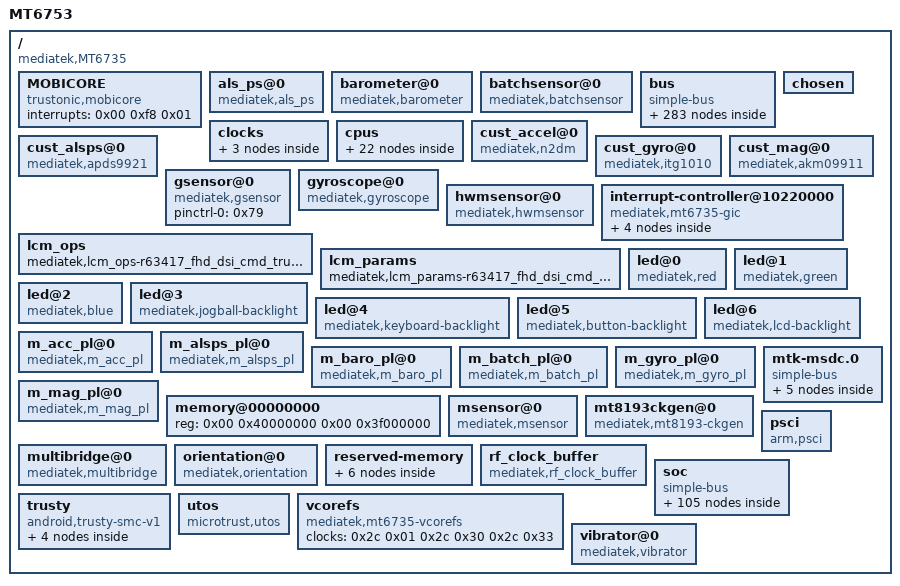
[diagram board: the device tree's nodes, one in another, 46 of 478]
/dts-v1/;

/ {
	#address-cells = <0x02>;
	#size-cells = <0x02>;
	compatible = "mediatek,MT6735";
	interrupt-parent = <0x01>;
	model = "MT6753";

	MOBICORE {
		compatible = "trustonic,mobicore";
		interrupts = <0x00 0xf8 0x01>;
	};

	als_ps@0 {
		compatible = "mediatek,als_ps";
		pinctrl-0 = <0x7a>;
		pinctrl-1 = <0x7b>;
		pinctrl-names = "pin_default\0pin_cfg";
		status = "okay";
	};

	barometer@0 {
		compatible = "mediatek,barometer";
	};

	batchsensor@0 {
		compatible = "mediatek,batchsensor";
	};

	bus {
		#address-cells = <0x01>;
		#size-cells = <0x01>;
		compatible = "simple-bus";
		ranges = <0x00 0x00 0x00 0xffffffff>;

		APMIXED@0x10209000 {
			compatible = "mediatek,APMIXED";
			reg = <0x10209000 0x1000>;
		};

		CKSYS@0x10210000 {
			compatible = "mediatek,CKSYS";
			reg = <0x10210000 0x1000>;
		};

		DEVAPC@10207000 {
			compatible = "mediatek,DEVAPC";
			interrupts = <0x00 0x86 0x08>;
			reg = <0x10207000 0x1000>;
		};

		DEVAPC_AO@10007000 {
			compatible = "mediatek,DEVAPC_AO";
			reg = <0x10007000 0x1000>;
		};

		EFUSEC@10206000 {
			compatible = "mediatek,EFUSEC";
			reg = <0x10206000 0x1000>;
		};

		EMI@0x10203000 {
			compatible = "mediatek,EMI";
			interrupts = <0x00 0x88 0x04>;
			reg = <0x10203000 0x1000>;
		};

		FHCTL@0x10209F00 {
			compatible = "mediatek,FHCTL";
			reg = <0x10209f00 0x100>;
		};

		G3D_CONFIG@0x13000000 {
			compatible = "mediatek,G3D_CONFIG";
			reg = <0x13000000 0x1000>;
		};

		INFRACFG_AO@0x10000000 {
			compatible = "mediatek,INFRACFG_AO";
			reg = <0x10000000 0x1000>;
		};

		MALI@0x13040000 {
			clock-frequency = <0x1ad27480>;
			clock-names = "mfg-main\0mfg-smi-common\0mtcmos-mfg\0mtcmos-display";
			clocks = <0x78 0x01 0x29 0x01 0x2d 0x05 0x2d 0x04>;
			compatible = "arm,malit720\0arm,mali-t72x\0arm,malit7xx\0arm,mali-midgard";
			interrupt-names = "JOB\0MMU\0GPU";
			interrupts = <0x00 0xd6 0x08 0x00 0xd5 0x08 0x00 0xd4 0x08>;
			reg = <0x13040000 0x4000>;
		};

		MCUCFG@0x10200000 {
			compatible = "mediatek,MCUCFG";
			interrupts = <0x00 0x47 0x04>;
			reg = <0x10200000 0x200>;
		};

		MTKFB@5e200000 {
			compatible = "mediatek,MTKFB";
			reg = <0x7f000000 0x1000000>;
		};

		PERICFG@0x10002000 {
			compatible = "mediatek,PERICFG";
			reg = <0x10002000 0x1000>;
		};

		SLEEP@0x10006000 {
			compatible = "mediatek,SLEEP";
			interrupts = <0x00 0xa5 0x08 0x00 0xa6 0x08 0x00 0xa7 0x08 0x00 0xa8 0x08>;
			reg = <0x10006000 0x1000>;
		};

		accdet@ {
			accdet-mic-mode = <0x01>;
			accdet-mic-vol = <0x07>;
			accdet-plugout-debounce = <0x14>;
			compatible = "mediatek,mt6735-accdet\0mediatek,mt6735m-accdet\0mediatek,mt6753-accdet";
			debounce = <0x05 0x3e800>;
			headset-four-key-threshold = <0x00 0x3a 0x79 0xc0 0x1c2>;
			headset-mode-setting = <0x146 0x82 0x01 0x44 0x800 0x800 0x20>;
			headset-three-key-threshold = <0x00 0x50 0xdc 0x1f4>;
			interrupt-parent = <0x0b>;
			interrupts = <0x05 0x08>;
			pinctrl-0 = <0x6d>;
			pinctrl-1 = <0x6e>;
			pinctrl-names = "default\0state_eint_as_int";
			status = "okay";
		};

		audio@11220000 {
			compatible = "mediatek,audio";
			interrupts = <0x00 0x90 0x08>;
			reg = <0x11220000 0x10000>;
		};

		bat_comm {
			compatible = "mediatek,battery";
		};

		bat_meter {
			compatible = "mediatek,bat_meter";
		};

		bat_notify {
			compatible = "mediatek,bat_notify";
		};

		btcvsd@10000000 {
			compatible = "mediatek,audio_bt_cvsd";
			interrupts = <0x00 0xe6 0x08>;
			offset = <0x700 0x800 0xfd0 0xfd4 0xfd8>;
			reg = <0x10000000 0x1000 0x18000000 0x10000 0x18080000 0x8000>;
		};

		bus_dbg@10208000 {
			compatible = "mediatek,bus_dbg-v1";
			interrupts = <0x00 0x89 0x08>;
			reg = <0x10208000 0x1000>;
		};

		c2k_sdio@0 {
			compatible = "mediatek,mt6735-c2k_sdio";
			interrupts = <0x00 0xde 0x08>;
		};

		ccci_off@0 {
			clock-names = "scp-sys-md1-main";
			clocks = <0x2d 0x01>;
			compatible = "mediatek,ccci_off";
		};

		cpu_dbgapb@10810000 {
			compatible = "mediatek,mt6735-dbg_debug";
			num = <0x08>;
			reg = <0x10810000 0x1000 0x10910000 0x1000 0x10a10000 0x1000 0x10b10000 0x1000 0x10c10000 0x1000 0x10d10000 0x1000 0x10e10000 0x1000 0x10f10000 0x1000>;
		};

		cqdma@10217c00 {
			compatible = "mediatek,cqdma";
			interrupts = <0x00 0x8f 0x08>;
			nr_channel = <0x01>;
			reg = <0x10217c00 0xc00>;
		};

		dbgapb_base@1011A000 {
			compatible = "mediatek,dbgapb_base";
			reg = <0x1011a000 0x100>;
		};

		dispsys@14007000 {
			compatible = "mediatek,dispsys";
			interrupts = <0x00 0xc1 0x08 0x00 0xd3 0x08 0x00 0xc2 0x08 0x00 0xc3 0x08 0x00 0xc4 0x08 0x00 0xc5 0x08 0x00 0xc6 0x08 0x00 0xc7 0x08 0x00 0xc8 0x08 0x00 0xc9 0x08 0x00 0x00 0x08 0x00 0x75 0x08 0x00 0x00 0x08 0x00 0xba 0x08 0x00 0xcb 0x08 0x00 0xcc 0x08 0x00 0xcd 0x08 0x00 0xb0 0x08 0x00 0x00 0x08 0x00 0x00 0x08 0x00 0x00 0x08 0x00 0x00 0x08 0x00 0x00 0x08 0x00 0x00 0x08 0x00 0x00 0x08 0x00 0x00 0x08 0x00 0x00 0x08 0x00 0x00 0x08 0x00 0x00 0x08 0x00 0x00 0x08 0x00 0x00 0x08 0x00 0xd2 0x08 0x00 0x00 0x08>;
			reg = <0x14007000 0x1000 0x14008000 0x1000 0x14009000 0x1000 0x1400a000 0x1000 0x1400b000 0x1000 0x1400c000 0x1000 0x1400d000 0x1000 0x1400e000 0x1000 0x1400f000 0x1000 0x14010000 0x1000 0x00 0x00 0x1100e000 0x1000 0x00 0x00 0x14015000 0x1000 0x14013000 0x1000 0x14014000 0x1000 0x14000000 0x1000 0x14016000 0x1000 0x14017000 0x1000 0x14018000 0x1000 0x10206000 0x1000 0x10210000 0x1000 0x10211a70 0x0c 0x10211974 0x0c 0x10211b70 0x0c 0x10206044 0x0c 0x10206514 0x0c 0x10206558 0x0c 0x102100a0 0x1000 0x10209260 0x1000 0x10209264 0x1000 0x14012000 0x1000 0x10209000 0x1000>;
		};

		dma@11000000 {
			compatible = "mediatek,ap_dma";
			interrupts = <0x00 0x72 0x08>;
			reg = <0x11000000 0x1000>;
		};

		eintc@10005000 {
			#interrupt-cells = <0x02>;
			compatible = "mediatek,mt-eic";
			interrupt-controller;
			interrupts = <0x00 0x99 0x04>;
			linux,phandle = <0x0b>;
			mediatek,deint_possible_irq = <0xbb 0xbc 0xbd 0xbe>;
			mediatek,mapping_table_entry = <0x00>;
			mediatek,max_deint_cnt = <0x04>;
			mediatek,max_eint_num = <0xd5>;
			phandle = <0x0b>;
			reg = <0x10005000 0x1000>;

			MD1_SIM1_HOT_PLUG_EINT@0 {
				compatible = "mediatek,MD1_SIM1_HOT_PLUG_EINT-eint";
				debounce = <0x00 0x186a0>;
				dedicated = <0x00 0x00>;
				interrupts = <0x00 0x08>;
				sockettype = <0x00 0x00>;
				src_pin = <0x00 0x00>;
				status = "okay";
			};

			pmic@206 {
				compatible = "mediatek, pmic-eint";
				debounce = <0xce 0x3e8>;
				interrupt-parent = <0x0b>;
				interrupts = <0xce 0x04>;
			};
		};

		gcpu@10216000 {
			compatible = "mediatek,gcpu";
			interrupts = <0x00 0x96 0x08>;
			reg = <0x10216000 0x1000>;
		};

		gf518m {
			compatible = "mediatek,gf518m";
			debounce = <0x08 0x00>;
			gf518m_vendor_gpio = <0x09 0x4e 0x00>;
			interrupt-parent = <0x0b>;
			interrupts = <0x08 0x08>;
			pinctrl-0 = <0x6f>;
			pinctrl-1 = <0x70>;
			pinctrl-2 = <0x71>;
			pinctrl-3 = <0x72>;
			pinctrl-4 = <0x73>;
			pinctrl-5 = <0x74>;
			pinctrl-6 = <0x75>;
			pinctrl-7 = <0x76>;
			pinctrl-8 = <0x77>;
			pinctrl-names = "pin_default\0goodix_pin_irq\0gf518m_reset_high\0gf518m_reset_low\0gf518m_miso_spi\0gf518m_mosi_spi\0gf518m_vendor_pu\0gf518m_vendor_pd\0goodix_pin_irq_pd";
			status = "okay";
			vgf518m-supply = <0x66>;
		};

		gps {
			compatible = "mediatek,mt3326-gps";
		};

		hallkey {
			compatible = "mediatek,mt6735-hallkey";
			debounce = <0x04 0x00>;
			interrupt-parent = <0x0b>;
			interrupts = <0x04 0x02>;
			status = "okay";
		};

		i2c@11007000 {
			#address-cells = <0x01>;
			#size-cells = <0x00>;
			cell-index = <0x00>;
			compatible = "mediatek,mt6753-i2c";
			def_speed = <0x64>;
			interrupts = <0x00 0x54 0x08 0x00 0x62 0x08>;
			reg = <0x11007000 0x1000>;

			cam_cal_drv@31 {
				compatible = "mediatek,cam_cal_drv";
				reg = <0x31>;
				status = "okay";
			};

			camera_main@10 {
				compatible = "mediatek,camera_main";
				reg = <0x10>;
				status = "okay";
			};

			camera_main_af@0c {
				compatible = "mediatek,camera_main_af";
				reg = <0x0c>;
				status = "okay";
			};

			camera_sub@3c {
				compatible = "mediatek,camera_sub";
				reg = <0x3c>;
				status = "okay";
			};
		};

		i2c@11008000 {
			#address-cells = <0x01>;
			#size-cells = <0x00>;
			cell-index = <0x01>;
			compatible = "mediatek,mt6753-i2c";
			def_speed = <0x64>;
			interrupts = <0x00 0x55 0x08 0x00 0x63 0x08>;
			reg = <0x11008000 0x1000>;

			cap_touch@38 {
				compatible = "mediatek,cap_touch";
				reg = <0x38>;
				status = "okay";
			};

			i2c_lcd_bias@73 {
				compatible = "mediatek,i2c_lcd_bias";
				reg = <0x73>;
				status = "okay";
			};

			strobe_main@30 {
				compatible = "mediatek,strobe_main";
				reg = <0x30>;
				status = "okay";
			};

			strobe_sub@32 {
				compatible = "mediatek,strobe_sub";
				reg = <0x32>;
				status = "okay";
			};

			synaptics_touch@20 {
				compatible = "mediatek,synaptics_touch";
				reg = <0x20>;
				status = "okay";
			};
		};

		i2c@11009000 {
			#address-cells = <0x01>;
			#size-cells = <0x00>;
			cell-index = <0x02>;
			compatible = "mediatek,mt6753-i2c";
			def_speed = <0x64>;
			interrupts = <0x00 0x56 0x08 0x00 0x64 0x08>;
			reg = <0x11009000 0x1000>;

			alsps@53 {
				compatible = "mediatek,alsps";
				reg = <0x53>;
				status = "okay";
			};

			flash@45 {
				compatible = "mediatek,flash";
				reg = <0x45>;
				status = "okay";
			};

			gsensor@09 {
				compatible = "mediatek,gsensor";
				reg = <0x09>;
				status = "okay";
			};

			gyro@68 {
				compatible = "mediatek,gyro";
				reg = <0x68>;
				status = "okay";
			};

			msensor@0c {
				compatible = "mediatek,msensor";
				reg = <0x0c>;
				status = "okay";
			};

			nfc@28 {
				compatible = "mediatek,nfc";
				reg = <0x28>;
				status = "okay";
			};
		};

		i2c@1100f000 {
			#address-cells = <0x01>;
			#size-cells = <0x00>;
			cell-index = <0x03>;
			compatible = "mediatek,mt6753-i2c";
			def_speed = <0x64>;
			interrupts = <0x00 0x57 0x08 0x00 0x65 0x08>;
			reg = <0x1100f000 0x1000>;
		};

		i2c@11012000 {
			#address-cells = <0x01>;
			#size-cells = <0x00>;
			cell-index = <0x04>;
			compatible = "mediatek,mt6753-i2c";
			def_speed = <0x64>;
			interrupts = <0x00 0x58 0x08 0x00 0x66 0x08>;
			reg = <0x11012000 0x1000>;
		};

		lcm {
			compatible = "mediatek,mt6753p1_64-lcm";
		};

		lcm_mode {
			compatible = "mediatek,lcm_mode";
			lcm_bl_gpio = <0x09 0x81 0x00>;
			lcm_power_gpio = <0x09 0x50 0x00>;
			pinctrl-0 = <0x50>;
			pinctrl-1 = <0x51>;
			pinctrl-2 = <0x52>;
			pinctrl-3 = <0x53>;
			pinctrl-4 = <0x54>;
			pinctrl-5 = <0x55>;
			pinctrl-6 = <0x56>;
			pinctrl-7 = <0x57>;
			pinctrl-8 = <0x58>;
			pinctrl-names = "default\0lcm_mode_00\0lcm_mode_01\0lcm_mode_02\0lcm_mode_03\0lcm_mode_04\0lcm_mode_05\0lcm_mode_06\0lcm_mode_07";
			status = "okay";
		};

		m4u@10205000 {
			cell-index = <0x00>;
			clock-names = "infra_m4u\0smi_common\0m4u_disp0_smi_larb0\0m4u_vdec0_vdec\0m4u_vdec1_larb\0m4u_img_image_larb2_smi\0m4u_venc_venc\0m4u_venc_larb";
			clocks = <0x16 0x09 0x29 0x01 0x29 0x02 0x2a 0x01 0x2a 0x02 0x32 0x01 0x2b 0x02 0x2b 0x01>;
			compatible = "mediatek,m4u";
			interrupts = <0x00 0x92 0x08>;
			reg = <0x10205000 0x1000>;
		};

		mcucfg@10200000 {
			compatible = "mediatek,mt6735-mcucfg";
			interrupts = <0x00 0x47 0x04>;
			reg = <0x10200000 0x200>;
		};

		mdc2k@3a00b01c {
			clock-names = "scp-sys-md2-main";
			clocks = <0x2d 0x02>;
			compatible = "mediatek,mdc2k";
			interrupts = <0x00 0xdd 0x02>;
			reg = <0x3a00b01c 0x10 0x1021c800 0x300 0x1021d800 0x300>;
		};

		mdcldma@1000A000 {
			compatible = "mediatek,mdcldma";
			interrupts = <0x00 0x91 0x04 0x00 0x8c 0x08 0x00 0xdf 0x02>;
			mediatek,cldma_capability = <0x02>;
			mediatek,md_id = <0x00>;
			mediatek,md_smem_size = <0x10000>;
			pinctrl-0 = <0x46>;
			pinctrl-1 = <0x47>;
			pinctrl-2 = <0x48>;
			pinctrl-3 = <0x49>;
			pinctrl-4 = <0x4a>;
			pinctrl-names = "default\0vsram_output_low\0vsram_output_high\0RFIC0_01_mode\0RFIC0_04_mode";
			reg = <0x1000a000 0x1000 0x1000b000 0x1000 0x1021a000 0x1000 0x1021b000 0x1000 0x1020a000 0x1000 0x1020b000 0x1000>;
		};

		mhl@0 {
			compatible = "mediatek,sii8348-hdmi";
		};

		mt_soc_codec_dummy_name@11220000 {
			compatible = "mediatek,mt_soc_codec_dummy";
		};

		mt_soc_codec_name@11220000 {
			compatible = "mediatek,mt_soc_codec_63xx";
		};

		mt_soc_dai_name@11220000 {
			compatible = "mediatek,mt_soc_dai_stub";
		};

		mt_soc_dl1_awb_pcm@11220000 {
			compatible = "mediatek,mt_soc_pcm_dl1_awb";
		};

		mt_soc_dl1_pcm@11220000 {
			audclk-gpio = <0x8f 0x00>;
			audmiso-gpio = <0x90 0x00>;
			audmosi-gpio = <0x91 0x00>;
			compatible = "mediatek,mt-soc-dl1-pcm";
			extspkamp-gpio = <0x75 0x00>;
			i2s1clk-gpio = <0x50 0x00>;
			i2s1dat-gpio = <0x4e 0x00>;
			i2s1mclk-gpio = <0x09 0x00>;
			i2s1ws-gpio = <0x4f 0x00>;
			interrupts = <0x00 0x90 0x08>;
			reg = <0x11220000 0x1000>;
			vowclk-gpio = <0x94 0x00>;
		};

		mt_soc_dl2_pcm@11220000 {
			compatible = "mediatek,mt_soc_pcm_dl2";
		};

		mt_soc_dummy_pcm@11220000 {
			compatible = "mediatek,mt_soc_pcm_dummy";
		};

		mt_soc_fm_i2s_awb_pcm@11220000 {
			compatible = "mediatek,mt_soc_pcm_fm_i2s_awb";
		};

		mt_soc_fm_i2s_pcm@11220000 {
			compatible = "mediatek,mt_soc_pcm_fm_i2s";
		};

		mt_soc_fm_mrgtx_pcm@11220000 {
			compatible = "mediatek,mt_soc_pcm_fmtx";
		};

		mt_soc_hdmi_pcm@11220000 {
			compatible = "mediatek,mt_soc_pcm_hdmi";
		};

		mt_soc_hp_impedance_pcm@11220000 {
			compatible = "mediatek,Mt_soc_pcm_hp_impedance";
		};

		mt_soc_i2s0_awb_pcm@11220000 {
			compatible = "mediatek,mt_soc_pcm_i2s0_awb";
		};

		mt_soc_i2s0_pcm@11220000 {
			compatible = "mediatek,mt_soc_pcm_dl1_i2s0";
		};

		mt_soc_i2s0dl1_pcm@11220000 {
			compatible = "mediatek,mt_soc_pcm_dl1_i2s0Dl1";
		};

		mt_soc_mrgrx_awb_pcm@11220000 {
			compatible = "mediatek,mt_soc_pcm_mrgrx_awb";
		};

		mt_soc_mrgrx_pcm@11220000 {
			compatible = "mediatek,mt_soc_pcm_mrgrx";
		};

		mt_soc_offload_gdma@11220000 {
			compatible = "mediatek,mt_soc_pcm_offload_gdma";
		};

		mt_soc_routing_dai_name@11220000 {
			compatible = "mediatek,mt_soc_dai_routing";
		};

		mt_soc_routing_pcm@11220000 {
			compatible = "mediatek,mt_soc_pcm_routing";
			i2s1clk-gpio = <0x07 0x06>;
			i2s1dat-gpio = <0x05 0x06>;
			i2s1mclk-gpio = <0x09 0x06>;
			i2s1ws-gpio = <0x06 0x06>;
		};

		mt_soc_tdmrx_pcm@11220000 {
			compatible = "mediatek,mt_soc_tdm_capture";
		};

		mt_soc_ul1_pcm@11220000 {
			compatible = "mediatek,mt_soc_pcm_capture";
		};

		mt_soc_ul2_pcm@11220000 {
			compatible = "mediatek,mt_soc_pcm_capture2";
		};

		mt_soc_uldlloopback_pcm@11220000 {
			compatible = "mediatek,mt_soc_pcm_uldlloopback";
		};

		mt_soc_voice_md1@11220000 {
			compatible = "mediatek,mt_soc_pcm_voice_md1";
		};

		mt_soc_voice_md1_bt@11220000 {
			compatible = "mediatek,mt_soc_pcm_voice_md1_bt";
		};

		mt_soc_voice_md2@11220000 {
			compatible = "mediatek,mt_soc_pcm_voice_md2";
		};

		mt_soc_voice_md2_bt@11220000 {
			compatible = "mediatek,mt_soc_pcm_voice_md2_bt";
		};

		mt_soc_voip_bt_in@11220000 {
			compatible = "mediatek,mt_soc_pcm_bt_dai";
		};

		mt_soc_voip_bt_out@11220000 {
			compatible = "mediatek,mt_soc_pcm_dl1_bt";
		};

		nfc@0 {
			compatible = "mediatek,nfc-gpio-v2";
			gpio-eint = <0x01>;
			gpio-irq = <0x02>;
			gpio-rst = <0x03>;
			gpio-ven = <0x04>;
			pinctrl-0 = <0x2e>;
			pinctrl-1 = <0x5a>;
			pinctrl-2 = <0x5b>;
			pinctrl-3 = <0x5c>;
			pinctrl-4 = <0x5d>;
			pinctrl-5 = <0x5e>;
			pinctrl-6 = <0x5f>;
			pinctrl-7 = <0x60>;
			pinctrl-names = "default\0ven_high\0ven_low\0rst_high\0rst_low\0eint_high\0eint_low\0irq_init";
			status = "okay";
		};

		pinctrl {
			#gpio-cells = <0x02>;
			compatible = "mediatek,mt6735-pinctrl";
			gpio-controller;
			linux,phandle = <0x09>;
			mediatek,pctl-regmap = <0x59>;
			phandle = <0x09>;
			pins-are-numbered;
			reg = <0x00 0x9bceb8 0x00 0x3e8>;

			8193ckgen_default {
				linux,phandle = <0x7e>;
				phandle = <0x7e>;
			};

			8193ckgen_dpi {
				linux,phandle = <0x80>;
				phandle = <0x80>;

				pins_cmd_dat {
					pins = <0x02>;
				};
			};

			8193ckgen_gpio {
				linux,phandle = <0x7f>;
				phandle = <0x7f>;

				pins_cmd_dat {
					bias-pull-up = <0x00>;
					output-high;
					pins = <0x00>;
					slew-rate = <0x01>;
				};
			};

			alspsdefaultcfg {
				linux,phandle = <0x7a>;
				phandle = <0x7a>;
			};

			alspspincfg {
				linux,phandle = <0x7b>;
				phandle = <0x7b>;

				pins_cmd_dat {
					bias-pull-up = <0x00>;
					pins = <0x200>;
					slew-rate = <0x00>;
				};
			};

			cam0@0 {
				linux,phandle = <0x38>;
				phandle = <0x38>;

				pins_cmd_dat {
					output-low;
					pins = <0x2c00>;
					slew-rate = <0x01>;
				};
			};

			cam0@1 {
				linux,phandle = <0x39>;
				phandle = <0x39>;

				pins_cmd_dat {
					output-high;
					pins = <0x2c00>;
					slew-rate = <0x01>;
				};
			};

			cam0@2 {
				linux,phandle = <0x3a>;
				phandle = <0x3a>;

				pins_cmd_dat {
					output-low;
					pins = <0x700>;
					slew-rate = <0x01>;
				};
			};

			cam0@3 {
				linux,phandle = <0x3b>;
				phandle = <0x3b>;

				pins_cmd_dat {
					output-high;
					pins = <0x700>;
					slew-rate = <0x01>;
				};
			};

			cam1@0 {
				linux,phandle = <0x3c>;
				phandle = <0x3c>;

				pins_cmd_dat {
					output-low;
					pins = <0xb00>;
					slew-rate = <0x01>;
				};
			};

			cam1@1 {
				linux,phandle = <0x3d>;
				phandle = <0x3d>;

				pins_cmd_dat {
					output-high;
					pins = <0xb00>;
					slew-rate = <0x01>;
				};
			};

			cam1@2 {
				linux,phandle = <0x3e>;
				phandle = <0x3e>;

				pins_cmd_dat {
					output-low;
					pins = <0xc00>;
					slew-rate = <0x01>;
				};
			};

			cam1@3 {
				linux,phandle = <0x3f>;
				phandle = <0x3f>;

				pins_cmd_dat {
					output-high;
					pins = <0xc00>;
					slew-rate = <0x01>;
				};
			};

			cam@0 {
				linux,phandle = <0x40>;
				phandle = <0x40>;

				pins_cmd_dat {
					output-low;
					pins = <0x3f00>;
					slew-rate = <0x01>;
				};
			};

			cam@1 {
				linux,phandle = <0x41>;
				phandle = <0x41>;

				pins_cmd_dat {
					output-high;
					pins = <0x3f00>;
					slew-rate = <0x01>;
				};
			};

			cam@2 {
				linux,phandle = <0x42>;
				phandle = <0x42>;

				pins_cmd_dat {
					output-low;
					pins = <0x4000>;
					slew-rate = <0x01>;
				};
			};

			cam@3 {
				linux,phandle = <0x43>;
				phandle = <0x43>;

				pins_cmd_dat {
					output-high;
					pins = <0x4000>;
					slew-rate = <0x01>;
				};
			};

			camdefault {
				linux,phandle = <0x37>;
				phandle = <0x37>;
			};

			clockbuf@1 {
				linux,phandle = <0x49>;
				phandle = <0x49>;

				pins_cmd0_dat {
					pins = <0x6e01>;
				};

				pins_cmd1_dat {
					pins = <0x6f01>;
				};

				pins_cmd2_dat {
					pins = <0x7001>;
				};

				pins_cmd3_dat {
					pins = <0x7101>;
				};

				pins_cmd4_dat {
					pins = <0x7201>;
				};
			};

			clockbuf@2 {
				linux,phandle = <0x4a>;
				phandle = <0x4a>;

				pins_cmd0_dat {
					pins = <0x6e04>;
				};

				pins_cmd1_dat {
					pins = <0x6f04>;
				};

				pins_cmd2_dat {
					pins = <0x7004>;
				};

				pins_cmd3_dat {
					pins = <0x7104>;
				};

				pins_cmd4_dat {
					pins = <0x7204>;
				};
			};

			default {
				linux,phandle = <0x2e>;
				phandle = <0x2e>;
			};

			drvvbus_high {
				linux,phandle = <0x65>;
				phandle = <0x65>;

				pins_cmd_dat {
					bias-pull-down = <0x00>;
					output-high;
					pins = <0x5300>;
					slew-rate = <0x01>;
				};
			};

			drvvbus_init {
				linux,phandle = <0x63>;
				phandle = <0x63>;

				pins_cmd_dat {
					bias-pull-up = <0x00>;
					pins = <0x5300>;
					slew-rate = <0x01>;
				};
			};

			drvvbus_low {
				linux,phandle = <0x64>;
				phandle = <0x64>;

				pins_cmd_dat {
					bias-pull-down = <0x00>;
					output-low;
					pins = <0x5300>;
					slew-rate = <0x01>;
				};
			};

			eint0default {
				linux,phandle = <0x67>;
				phandle = <0x67>;
			};

			eint5default {
				linux,phandle = <0x6d>;
				phandle = <0x6d>;
			};

			eint@0 {
				linux,phandle = <0x68>;
				phandle = <0x68>;

				pins_cmd_dat {
					bias-disable;
					pins = <0x900>;
					slew-rate = <0x00>;
				};
			};

			eint@5 {
				linux,phandle = <0x6e>;
				phandle = <0x6e>;

				pins_cmd_dat {
					bias-disable;
					pins = <0x500>;
					slew-rate = <0x00>;
				};
			};

			eintoutput0 {
				linux,phandle = <0x69>;
				phandle = <0x69>;

				pins_cmd_dat {
					output-low;
					pins = <0x900>;
					slew-rate = <0x01>;
				};
			};

			eintoutput1 {
				linux,phandle = <0x6a>;
				phandle = <0x6a>;

				pins_cmd_dat {
					output-high;
					pins = <0x900>;
					slew-rate = <0x01>;
				};
			};

			flashlight@0 {
				linux,phandle = <0x44>;
				phandle = <0x44>;

				pins_cmd_dat {
					output-low;
					pins = <0x4d00>;
					slew-rate = <0x01>;
				};
			};

			flashlight@1 {
				linux,phandle = <0x45>;
				phandle = <0x45>;

				pins_cmd_dat {
					output-high;
					pins = <0x4d00>;
					slew-rate = <0x01>;
				};
			};

			gf518m_miso_spi {
				linux,phandle = <0x73>;
				phandle = <0x73>;

				pins_cmd_dat {
					bias-pull-up = <0x00>;
					pins = <0x4301>;
					slew-rate = <0x00>;
				};
			};

			gf518m_mosi_spi {
				linux,phandle = <0x74>;
				phandle = <0x74>;

				pins_cmd_dat {
					bias-pull-up = <0x00>;
					output-high;
					pins = <0x4401>;
					slew-rate = <0x01>;
				};
			};

			gf518m_reset_high {
				linux,phandle = <0x71>;
				phandle = <0x71>;

				pins_cmd_dat {
					bias-disable;
					output-high;
					pins = <0xa00>;
					slew-rate = <0x01>;
				};
			};

			gf518m_reset_low {
				linux,phandle = <0x72>;
				phandle = <0x72>;

				pins_cmd_dat {
					bias-disable;
					output-low;
					pins = <0xa00>;
					slew-rate = <0x01>;
				};
			};

			gf518m_vendor_pd {
				linux,phandle = <0x76>;
				phandle = <0x76>;

				pins_cmd_dat {
					bias-pull-down = <0x00>;
					pins = <0x4e00>;
					slew-rate = <0x00>;
				};
			};

			gf518m_vendor_pu {
				linux,phandle = <0x75>;
				phandle = <0x75>;

				pins_cmd_dat {
					bias-pull-up = <0x00>;
					output-high;
					pins = <0x4e00>;
					slew-rate = <0x00>;
				};
			};

			goodix_pin_irq {
				linux,phandle = <0x70>;
				phandle = <0x70>;

				pins_cmd_dat {
					bias-disable;
					pins = <0x800>;
					slew-rate = <0x00>;
				};
			};

			goodix_pin_irq_pd {
				linux,phandle = <0x77>;
				phandle = <0x77>;

				pins_cmd_dat {
					bias-pull-down = <0x00>;
					pins = <0x800>;
					slew-rate = <0x00>;
				};
			};

			gpslna@0 {
				linux,phandle = <0x2f>;
				phandle = <0x2f>;

				pins_cmd_dat {
					bias-disable;
					output-low;
					pins = <0x4f00>;
					slew-rate = <0x00>;
				};
			};

			gpslna@1 {
				linux,phandle = <0x30>;
				phandle = <0x30>;

				pins_cmd_dat {
					output-high;
					pins = <0x4f00>;
					slew-rate = <0x01>;
				};
			};

			gpslna@2 {
				linux,phandle = <0x31>;
				phandle = <0x31>;

				pins_cmd_dat {
					output-low;
					pins = <0x4f00>;
					slew-rate = <0x01>;
				};
			};

			gsensorpincfg {
				linux,phandle = <0x79>;
				phandle = <0x79>;

				pins_cmd_dat {
					bias-pull-down = <0x00>;
					pins = <0x700>;
					slew-rate = <0x00>;
				};
			};

			gyrodefaultcfg {
				linux,phandle = <0x7c>;
				phandle = <0x7c>;
			};

			gyropincfg {
				linux,phandle = <0x7d>;
				phandle = <0x7d>;

				pins_cmd_dat {
					bias-pull-down = <0x00>;
					pins = <0x4300>;
					slew-rate = <0x00>;
				};
			};

			iddig_irq_init {
				linux,phandle = <0x62>;
				phandle = <0x62>;

				pins_cmd_dat {
					bias-pull-up = <0x00>;
					pins = <0x01>;
					slew-rate = <0x00>;
				};
			};

			lcm_mode@0 {
				linux,phandle = <0x51>;
				phandle = <0x51>;

				pins_cmd_dat {
					pins = <0x5000>;
				};
			};

			lcm_mode@1 {
				linux,phandle = <0x52>;
				phandle = <0x52>;

				pins_cmd_dat {
					pins = <0x5001>;
				};
			};

			lcm_mode@2 {
				linux,phandle = <0x53>;
				phandle = <0x53>;

				pins_cmd_dat {
					pins = <0x5002>;
				};
			};

			lcm_mode@3 {
				linux,phandle = <0x54>;
				phandle = <0x54>;

				pins_cmd_dat {
					pins = <0x5003>;
				};
			};

			lcm_mode@4 {
				linux,phandle = <0x55>;
				phandle = <0x55>;

				pins_cmd_dat {
					pins = <0x5004>;
				};
			};

			lcm_mode@5 {
				linux,phandle = <0x56>;
				phandle = <0x56>;

				pins_cmd_dat {
					pins = <0x5005>;
				};
			};

			lcm_mode@6 {
				linux,phandle = <0x57>;
				phandle = <0x57>;

				pins_cmd_dat {
					pins = <0x5006>;
				};
			};

			lcm_mode@7 {
				linux,phandle = <0x58>;
				phandle = <0x58>;

				pins_cmd_dat {
					pins = <0x5007>;
				};
			};

			lcm_mode_default {
				linux,phandle = <0x50>;
				phandle = <0x50>;

				pins_cmd_dat {
					pins = <0x5000>;
				};
			};

			mmc0@default {
				linux,phandle = <0x02>;
				phandle = <0x02>;

				pins_clk {
					drive-strength = [02];
				};

				pins_cmd {
					drive-strength = [02];
				};

				pins_dat {
					drive-strength = [02];
				};

				pins_ds {
					drive-strength = [02];
				};

				pins_rst {
					drive-strength = [02];
				};
			};

			mmc0@register_default {
				cmd_edge = [01];
				cmdrddly = [00];
				cmdrrddly = [00];
				dat0rddly = [00];
				dat1rddly = [00];
				dat2rddly = [00];
				dat3rddly = [00];
				dat4rddly = [00];
				dat5rddly = [00];
				dat6rddly = [00];
				dat7rddly = [00];
				datwrddly = [00];
				ett-hs200-cells = <0x0c>;
				ett-hs200-default = <0xb0 0x380 0x00 0xb0 0x7c00 0x00 0xb4 0x38 0x01 0x04 0x02 0x01 0xf0 0x1f0000 0x0f 0xf0 0x7c00000 0x00 0xb4 0x07 0x01 0xf0 0x1f 0x0f 0x04 0x400 0x01 0xf8 0x1f000000 0x0f 0xf0 0x1f00 0x16 0x04 0x04 0x00>;
				ett-hs400-cells = <0x08>;
				ett-hs400-default = <0xb0 0x380 0x00 0xb0 0x7c00 0x00 0x188 0x7c 0x02 0x188 0x1f000 0x0e 0xb4 0x38 0x01 0x04 0x02 0x00 0xf0 0x1f0000 0x0f 0xf0 0x7c00000 0x0d>;
				linux,phandle = <0x03>;
				phandle = <0x03>;
				rdata_edge = [01];
				wdata_edge = [01];
			};

			mmc1@ddr50 {
				linux,phandle = <0x07>;
				phandle = <0x07>;

				pins_clk {
					drive-strength = [03];
				};

				pins_cmd {
					drive-strength = [02];
				};

				pins_dat {
					drive-strength = [02];
				};
			};

			mmc1@default {
				linux,phandle = <0x04>;
				phandle = <0x04>;

				pins_clk {
					drive-strength = [03];
				};

				pins_cmd {
					drive-strength = [03];
				};

				pins_dat {
					drive-strength = [03];
				};
			};

			mmc1@register_default {
				cmd_edge = [01];
				cmdrddly = [00];
				cmdrrddly = [00];
				dat0rddly = [00];
				dat1rddly = [00];
				dat2rddly = [00];
				dat3rddly = [00];
				datwrddly = [00];
				linux,phandle = <0x08>;
				phandle = <0x08>;
				rdata_edge = [01];
				wdata_edge = [01];
			};

			mmc1@sdr104 {
				linux,phandle = <0x05>;
				phandle = <0x05>;

				pins_clk {
					drive-strength = [03];
				};

				pins_cmd {
					drive-strength = [02];
				};

				pins_dat {
					drive-strength = [02];
				};
			};

			mmc1@sdr50 {
				linux,phandle = <0x06>;
				phandle = <0x06>;

				pins_clk {
					drive-strength = [03];
				};

				pins_cmd {
					drive-strength = [02];
				};

				pins_dat {
					drive-strength = [02];
				};
			};

			pin_default {
				linux,phandle = <0x6f>;
				phandle = <0x6f>;
			};

			rstoutput0 {
				linux,phandle = <0x6b>;
				phandle = <0x6b>;

				pins_cmd_dat {
					output-low;
					pins = <0x3e00>;
					slew-rate = <0x01>;
				};
			};

			rstoutput1 {
				linux,phandle = <0x6c>;
				phandle = <0x6c>;

				pins_cmd_dat {
					output-high;
					pins = <0x3e00>;
					slew-rate = <0x01>;
				};
			};

			ssw0default {
				linux,phandle = <0x4b>;
				phandle = <0x4b>;
			};

			ssw@1 {
				linux,phandle = <0x4c>;
				phandle = <0x4c>;

				pins_cmd0_dat {
					pins = <0x805>;
				};

				pins_cmd1_dat {
					pins = <0x904>;
				};
			};

			ssw@2 {
				linux,phandle = <0x4d>;
				phandle = <0x4d>;

				pins_cmd0_dat {
					pins = <0x802>;
				};

				pins_cmd1_dat {
					pins = <0x904>;
				};
			};

			ssw@3 {
				linux,phandle = <0x4e>;
				phandle = <0x4e>;

				pins_cmd0_dat {
					pins = <0xa301>;
					slew-rate = <0x01>;
				};

				pins_cmd1_dat {
					pins = <0xa401>;
					slew-rate = <0x01>;
				};

				pins_cmd2_dat {
					bias-pull-up = <0x00>;
					pins = <0xa501>;
					slew-rate = <0x00>;
				};

				pins_cmd3_dat {
					pins = <0xa001>;
					slew-rate = <0x01>;
				};

				pins_cmd4_dat {
					pins = <0xa101>;
					slew-rate = <0x01>;
				};

				pins_cmd5_dat {
					bias-pull-up = <0x00>;
					pins = <0xa201>;
					slew-rate = <0x00>;
				};
			};

			ssw@4 {
				linux,phandle = <0x4f>;
				phandle = <0x4f>;

				pins_cmd0_dat {
					pins = <0xa304>;
				};

				pins_cmd1_dat {
					pins = <0xa404>;
				};

				pins_cmd2_dat {
					pins = <0xa504>;
				};

				pins_cmd3_dat {
					pins = <0xa001>;
				};

				pins_cmd4_dat {
					pins = <0xa101>;
				};

				pins_cmd5_dat {
					pins = <0xa201>;
				};
			};

			state_eint_high {
				linux,phandle = <0x5e>;
				phandle = <0x5e>;

				pins_cmd_dat {
					output-high;
					pins = <0x100>;
					slew-rate = <0x01>;
				};
			};

			state_eint_low {
				linux,phandle = <0x5f>;
				phandle = <0x5f>;

				pins_cmd_dat {
					output-low;
					pins = <0x100>;
					slew-rate = <0x01>;
				};
			};

			state_irq_init {
				linux,phandle = <0x60>;
				phandle = <0x60>;

				pins_cmd_dat {
					bias-pull-down = <0x00>;
					pins = <0x200>;
					slew-rate = <0x00>;
				};
			};

			state_rst_high {
				linux,phandle = <0x5c>;
				phandle = <0x5c>;

				pins_cmd_dat {
					output-high;
					pins = <0x300>;
					slew-rate = <0x01>;
				};
			};

			state_rst_low {
				linux,phandle = <0x5d>;
				phandle = <0x5d>;

				pins_cmd_dat {
					output-low;
					pins = <0x300>;
					slew-rate = <0x01>;
				};
			};

			state_ven_high {
				linux,phandle = <0x5a>;
				phandle = <0x5a>;

				pins_cmd_dat {
					output-high;
					pins = <0x400>;
					slew-rate = <0x01>;
				};
			};

			state_ven_low {
				linux,phandle = <0x5b>;
				phandle = <0x5b>;

				pins_cmd_dat {
					output-low;
					pins = <0x400>;
					slew-rate = <0x01>;
				};
			};

			vsram0default {
				linux,phandle = <0x46>;
				phandle = <0x46>;
			};

			vsram@1 {
				linux,phandle = <0x47>;
				phandle = <0x47>;

				pins_cmd_dat {
					output-low;
					pins = <0x8c00>;
					slew-rate = <0x01>;
				};
			};

			vsram@2 {
				linux,phandle = <0x48>;
				phandle = <0x48>;

				pins_cmd_dat {
					output-high;
					pins = <0x8c00>;
					slew-rate = <0x01>;
				};
			};
		};

		pwm@11006000 {
			compatible = "mediatek,pwm";
			interrupts = <0x00 0x4d 0x08>;
			reg = <0x11006000 0x1000>;
		};

		pwrap {
			compatible = "mediatek,PWRAP";
			interrupts = <0x00 0xa3 0x04>;
			reg = <0x10001000 0x1000>;
		};

		simswitch@0 {
			compatible = "mediatek,sim_switch";
			pinctrl-0 = <0x4b>;
			pinctrl-1 = <0x4c>;
			pinctrl-2 = <0x4d>;
			pinctrl-3 = <0x4e>;
			pinctrl-4 = <0x4f>;
			pinctrl-names = "default\0hot_plug_mode1\0hot_plug_mode2\0two_sims_bound_to_md1\0sim1_md3_sim2_md1";
		};

		syscfg_pctl_a {
			compatible = "mediatek,mt6735-pctl-a-syscfg\0syscon";
			linux,phandle = <0x59>;
			phandle = <0x59>;
			reg = <0x00 0x9bceb8 0x00 0x3e8>;
		};

		touch@ {
			compatible = "mediatek,mt6735-touch\0mediatek,mt6735m-touch\0mediatek,mt6753-touch";
			debounce = <0x09 0x00>;
			interrupt-parent = <0x0b>;
			interrupts = <0x09 0x01>;
			pinctrl-0 = <0x67>;
			pinctrl-1 = <0x68>;
			pinctrl-2 = <0x69>;
			pinctrl-3 = <0x6a>;
			pinctrl-4 = <0x6b>;
			pinctrl-5 = <0x6c>;
			pinctrl-names = "default\0state_eint_as_int\0state_eint_output0\0state_eint_output1\0state_rst_output0\0state_rst_output1";
			status = "okay";
			tpd-filter-custom-prameters = <0x00 0x00 0x00 0x00 0x00 0x00 0x00 0x00 0x00 0x00 0x00 0x00>;
			tpd-filter-custom-speed = <0x00 0x00 0x00>;
			tpd-filter-enable = <0x00>;
			tpd-filter-pixel-density = <0xba>;
			tpd-key-dim-local = <0x5a 0x373 0x64 0x28 0xe6 0x373 0x64 0x28 0x172 0x373 0x64 0x28 0x00 0x00 0x00 0x00>;
			tpd-key-local = <0x8b 0xac 0x9e 0x00>;
			tpd-key-num = <0x03>;
			tpd-max-touch-num = <0x05>;
			tpd-resolution = <0x438 0x780>;
			use-tpd-button = <0x00>;
			vtouch-supply = <0x66>;
		};

		usb20@11200000 {
			VUSB33-supply = <0x61>;
			cell-index = <0x00>;
			clock-names = "usb0";
			clocks = <0x0a 0x0b>;
			compatible = "mediatek,mt6735-usb20";
			dma = <0x01>;
			dma_channels = <0x08>;
			drvvbus_gpio = <0x53 0x02>;
			dyn_fifo = <0x01>;
			iddig_gpio = <0x00 0x01>;
			interrupts = <0x00 0x48 0x08>;
			mode = <0x02>;
			multipoint = <0x01>;
			num_eps = <0x10>;
			pinctrl-0 = <0x2e>;
			pinctrl-1 = <0x62>;
			pinctrl-2 = <0x63>;
			pinctrl-3 = <0x64>;
			pinctrl-4 = <0x65>;
			pinctrl-names = "default\0iddig_irq_init\0drvvbus_init\0drvvbus_low\0drvvbus_high";
			reg = <0x11200000 0x10000 0x11210000 0x10000>;
			soft_con = <0x01>;
			status = "okay";
		};

		wifi@180F0000 {
			compatible = "mediatek,wifi";
			interrupts = <0x00 0xe4 0x08>;
			reg = <0x180f0000 0x5c>;
		};
	};

	chosen {
		bootargs = "console=tty0 console=ttyMT0,921600n1 root=/dev/ram initrd=0x44000000,0x300000 loglevel=8 androidboot.hardware=mt6735";
	};

	clocks {

		clk26m {
			#clock-cells = <0x00>;
			clock-frequency = <0x18cba80>;
			compatible = "fixed-clock";
		};

		clk32k {
			#clock-cells = <0x00>;
			clock-frequency = <0x7d00>;
			compatible = "fixed-clock";
		};

		clk_null {
			#clock-cells = <0x00>;
			clock-frequency = <0x00>;
			compatible = "fixed-clock";
		};
	};

	cpus {
		#address-cells = <0x01>;
		#size-cells = <0x00>;

		cpu-map {

			cluster0 {

				core0 {
					cpu = <0x0e>;
				};

				core1 {
					cpu = <0x0f>;
				};

				core2 {
					cpu = <0x10>;
				};

				core3 {
					cpu = <0x11>;
				};
			};

			cluster1 {

				core0 {
					cpu = <0x12>;
				};

				core1 {
					cpu = <0x13>;
				};

				core2 {
					cpu = <0x14>;
				};

				core3 {
					cpu = <0x15>;
				};
			};
		};

		cpu@000 {
			clock-frequency = "M|m";
			compatible = "arm,cortex-a53";
			cpu-idle-states = <0x0c 0x0c 0x0d 0x0d>;
			cpu-release-addr = <0x00 0x40000200>;
			device_type = "cpu";
			enable-method = "mt-boot";
			linux,phandle = <0x0e>;
			phandle = <0x0e>;
			reg = <0x00>;
		};

		cpu@001 {
			clock-frequency = "M|m";
			compatible = "arm,cortex-a53";
			cpu-idle-states = <0x0c 0x0c 0x0d 0x0d>;
			cpu-release-addr = <0x00 0x40000200>;
			device_type = "cpu";
			enable-method = "mt-boot";
			linux,phandle = <0x0f>;
			phandle = <0x0f>;
			reg = <0x01>;
		};

		cpu@002 {
			clock-frequency = "M|m";
			compatible = "arm,cortex-a53";
			cpu-idle-states = <0x0c 0x0c 0x0d 0x0d>;
			cpu-release-addr = <0x00 0x40000200>;
			device_type = "cpu";
			enable-method = "mt-boot";
			linux,phandle = <0x10>;
			phandle = <0x10>;
			reg = <0x02>;
		};

		cpu@003 {
			clock-frequency = "M|m";
			compatible = "arm,cortex-a53";
			cpu-idle-states = <0x0c 0x0c 0x0d 0x0d>;
			cpu-release-addr = <0x00 0x40000200>;
			device_type = "cpu";
			enable-method = "mt-boot";
			linux,phandle = <0x11>;
			phandle = <0x11>;
			reg = <0x03>;
		};

		cpu@100 {
			clock-frequency = "M|m";
			compatible = "arm,cortex-a53";
			cpu-idle-states = <0x0c 0x0c 0x0d 0x0d>;
			cpu-release-addr = <0x00 0x40000200>;
			device_type = "cpu";
			enable-method = "mt-boot";
			linux,phandle = <0x12>;
			phandle = <0x12>;
			reg = <0x100>;
		};

		cpu@101 {
			clock-frequency = "M|m";
			compatible = "arm,cortex-a53";
			cpu-idle-states = <0x0c 0x0c 0x0d 0x0d>;
			cpu-release-addr = <0x00 0x40000200>;
			device_type = "cpu";
			enable-method = "mt-boot";
			linux,phandle = <0x13>;
			phandle = <0x13>;
			reg = <0x101>;
		};

		cpu@102 {
			clock-frequency = "M|m";
			compatible = "arm,cortex-a53";
			cpu-idle-states = <0x0c 0x0c 0x0d 0x0d>;
			cpu-release-addr = <0x00 0x40000200>;
			device_type = "cpu";
			enable-method = "mt-boot";
			linux,phandle = <0x14>;
			phandle = <0x14>;
			reg = <0x102>;
		};

		cpu@103 {
			clock-frequency = "M|m";
			compatible = "arm,cortex-a53";
			cpu-idle-states = <0x0c 0x0c 0x0d 0x0d>;
			cpu-release-addr = <0x00 0x40000200>;
			device_type = "cpu";
			enable-method = "mt-boot";
			linux,phandle = <0x15>;
			phandle = <0x15>;
			reg = <0x103>;
		};

		idle-states {
			entry-method = "arm,psci";

			cluster-sleep-0 {
				arm,psci-suspend-param = <0x1010000>;
				compatible = "arm,idle-state";
				entry-latency-us = <0x320>;
				exit-latency-us = <0x3e8>;
				linux,phandle = <0x0c>;
				min-residency-us = <0x7d0>;
				phandle = <0x0c>;
			};

			cpu-sleep-0-0 {
				arm,psci-suspend-param = <0x10000>;
				compatible = "arm,idle-state";
				entry-latency-us = <0x258>;
				exit-latency-us = <0x258>;
				linux,phandle = <0x0d>;
				min-residency-us = <0x4b0>;
				phandle = <0x0d>;
			};
		};
	};

	cust_accel@0 {
		compatible = "mediatek,n2dm";
		direction = <0x03>;
		firlen = <0x00>;
		i2c_addr = <0x09 0x00 0x00 0x00>;
		i2c_num = <0x02>;
		is_batch_supported = <0x00>;
		power_id = <0xffff>;
		power_vol = <0x00>;
	};

	cust_alsps@0 {
		als_level = <0x00 0x101 0x27d 0x403 0x8f9 0x15d4 0x1a4a 0x2c25 0x4fe1 0x64a8 0x7992 0xb1f0 0xe251 0xe251 0xe251>;
		als_value = <0x00 0x84 0x130 0x1f6 0x3ec 0x7d3 0xbbe 0x138e 0x1f44 0x2710 0x2ee0 0x3e80 0x4e20 0x4e20 0x4e20 0x4e20>;
		compatible = "mediatek,apds9921";
		i2c_addr = <0x53 0x00 0x00 0x00>;
		i2c_num = <0x01>;
		is_batch_supported_als = <0x01>;
		is_batch_supported_ps = <0x01>;
		polling_mode_als = <0x01>;
		polling_mode_ps = <0x00>;
		power_id = <0xffff>;
		power_vol = <0x00>;
		ps_threshold_high = <0x46>;
		ps_threshold_low = <0x28>;
	};

	cust_gyro@0 {
		compatible = "mediatek,itg1010";
		direction = <0x03>;
		firlen = <0x00>;
		i2c_addr = <0x68 0x00 0x00 0x00>;
		i2c_num = <0x02>;
		is_batch_supported = <0x00>;
		power_id = <0xffff>;
		power_vol = <0x00>;
	};

	cust_mag@0 {
		compatible = "mediatek,akm09911";
		direction = <0x03>;
		i2c_addr = <0x0c 0x00 0x00 0x00>;
		i2c_num = <0x02>;
		is_batch_supported = <0x00>;
		power_id = <0xffff>;
		power_vol = <0x00>;
	};

	gsensor@0 {
		compatible = "mediatek,gsensor";
		pinctrl-0 = <0x79>;
		pinctrl-names = "pin_cfg";
		status = "okay";
	};

	gyroscope@0 {
		compatible = "mediatek,gyroscope";
		debounce = <0x43 0x00>;
		interrupt-parent = <0x0b>;
		interrupts = <0x43 0x08>;
		pinctrl-0 = <0x7c>;
		pinctrl-1 = <0x7d>;
		pinctrl-names = "pin_default\0pin_cfg";
		status = "okay";
	};

	hwmsensor@0 {
		compatible = "mediatek,hwmsensor";
	};

	interrupt-controller@10220000 {
		#address-cells = <0x00>;
		#interrupt-cells = <0x03>;
		compatible = "mediatek,mt6735-gic";
		interrupt-controller;
		linux,phandle = <0x01>;
		mediatek,wdt_irq = <0xa0>;
		phandle = <0x01>;
		reg = <0x00 0x10221000 0x00 0x1000 0x00 0x10222000 0x00 0x1000 0x00 0x10200620 0x00 0x1000>;

		gic-cpuif@0 {
			compatible = "arm,gic-cpuif";
			cpu = <0x0e>;
			cpuif-id = <0x00>;
		};

		gic-cpuif@1 {
			compatible = "arm,gic-cpuif";
			cpu = <0x0f>;
			cpuif-id = <0x01>;
		};

		gic-cpuif@2 {
			compatible = "arm,gic-cpuif";
			cpu = <0x10>;
			cpuif-id = <0x02>;
		};

		gic-cpuif@3 {
			compatible = "arm,gic-cpuif";
			cpu = <0x11>;
			cpuif-id = <0x03>;
		};
	};

	lcm_ops {
		backlight = <0x04 0x05 0x03 0x51 0x01 0xff>;
		compare_id = <0x03 0x01 0x01 0x01 0x03 0x02 0x01 0x01 0x03 0x01 0x01 0x00 0x03 0x02 0x01 0x0a 0x03 0x01 0x01 0x01 0x03 0x02 0x01 0x0a 0x04 0x04 0x05 0x01 0x00 0x37 0x02 0x00 0x04 0x07 0x03 0xf4 0x01 0x95>;
		compatible = "mediatek,lcm_ops-r63417_fhd_dsi_cmd_truly_nt50358_drv";
		init = <0x01 0x01 0x01 0x00 0x01 0x02 0x01 0x01 0x01 0x03 0x01 0x01 0x03 0x02 0x01 0x0a 0x02 0x01 0x02 0x00 0x0a 0x02 0x01 0x02 0x01 0x0a 0x03 0x01 0x01 0x01 0x03 0x02 0x01 0x01 0x03 0x01 0x01 0x00 0x03 0x02 0x01 0x0a 0x03 0x01 0x01 0x01 0x03 0x02 0x01 0x0a 0x04 0x05 0x03 0xb0 0x01 0x00 0x04 0x05 0x03 0xd6 0x01 0x01 0x04 0x05 0x03 0x51 0x01 0xff 0x04 0x05 0x03 0x53 0x01 0x0c 0x04 0x05 0x2a 0xc6 0x28 0x77 0x01 0x71 0x07 0x65 0x00 0x00 0x00 0x00 0x00 0x00 0x00 0x00 0x00 0x00 0x00 0x00 0x09 0x19 0x09 0x77 0x01 0x71 0x07 0x65 0x00 0x00 0x00 0x00 0x00 0x00 0x00 0x00 0x00 0x00 0x00 0x00 0x09 0x19 0x09 0x04 0x05 0x20 0xc7 0x1e 0x01 0x0c 0x14 0x1e 0x2d 0x3c 0x48 0x58 0x3d 0x44 0x4f 0x5c 0x65 0x6d 0x75 0x01 0x0c 0x14 0x1d 0x2c 0x39 0x44 0x54 0x39 0x41 0x4d 0x5a 0x63 0x6b 0x74 0x04 0x05 0x15 0xc8 0x13 0x01 0x00 0xff 0xff 0x00 0xfc 0x00 0x00 0xff 0xff 0x00 0xfc 0x00 0x00 0xff 0xff 0x00 0xfc 0x00 0x04 0x05 0x03 0x35 0x01 0x00 0x04 0x05 0x04 0xb6 0x02 0x3a 0xd3 0x04 0x05 0x02 0x29 0x00 0x04 0x05 0x02 0x11 0x00 0x03 0x02 0x01 0x78>;
		suspend = <0x04 0x05 0x02 0x28 0x00 0x03 0x02 0x01 0x14 0x04 0x05 0x02 0x10 0x00 0x04 0x05 0x03 0xb0 0x01 0x00 0x04 0x05 0x03 0xb1 0x01 0x01 0x03 0x02 0x01 0x50 0x03 0x02 0x01 0x0a 0x01 0x01 0x01 0x00 0x01 0x02 0x01 0x01 0x01 0x03 0x01 0x00>;
	};

	lcm_params {
		compatible = "mediatek,lcm_params-r63417_fhd_dsi_cmd_truly_nt50358_drv";
		lcm_params-dbi-clock_freq;
		lcm_params-dbi-cpu_write_bits;
		lcm_params-dbi-ctrl_io_driving_current;
		lcm_params-dbi-data_format;
		lcm_params-dbi-data_width;
		lcm_params-dbi-io_driving_current;
		lcm_params-dbi-msb_io_driving_current;
		lcm_params-dbi-parallel-params0;
		lcm_params-dbi-parallel-params1;
		lcm_params-dbi-port;
		lcm_params-dbi-serial-params0;
		lcm_params-dbi-serial-params1;
		lcm_params-dbi-serial-params2;
		lcm_params-dbi-te_edge_polarity;
		lcm_params-dbi-te_hs_delay_cnt;
		lcm_params-dbi-te_mode;
		lcm_params-dbi-te_vs_width_cnt;
		lcm_params-dbi-te_vs_width_cnt_div;
		lcm_params-dpi-PLL_CLOCK;
		lcm_params-dpi-bg_height;
		lcm_params-dpi-bg_width;
		lcm_params-dpi-bit_swap;
		lcm_params-dpi-clk_pol;
		lcm_params-dpi-de_pol;
		lcm_params-dpi-dpi_clk_div;
		lcm_params-dpi-dpi_clk_duty;
		lcm_params-dpi-dpi_clock;
		lcm_params-dpi-embsync;
		lcm_params-dpi-format;
		lcm_params-dpi-height;
		lcm_params-dpi-hsync_back_porch;
		lcm_params-dpi-hsync_front_porch;
		lcm_params-dpi-hsync_pol;
		lcm_params-dpi-hsync_pulse_width;
		lcm_params-dpi-i2x_edge;
		lcm_params-dpi-i2x_en;
		lcm_params-dpi-intermediat_buffer_num;
		lcm_params-dpi-io_driving_current;
		lcm_params-dpi-is_serial_output;
		lcm_params-dpi-lsb_io_driving_current;
		lcm_params-dpi-lvds_tx_en;
		lcm_params-dpi-mipi_pll_clk_div1;
		lcm_params-dpi-mipi_pll_clk_div2;
		lcm_params-dpi-mipi_pll_clk_fbk_div;
		lcm_params-dpi-mipi_pll_clk_ref;
		lcm_params-dpi-rgb_order;
		lcm_params-dpi-ssc_disable;
		lcm_params-dpi-ssc_range;
		lcm_params-dpi-vsync_back_porch;
		lcm_params-dpi-vsync_front_porch;
		lcm_params-dpi-vsync_pol;
		lcm_params-dpi-vsync_pulse_width;
		lcm_params-dpi-width;
		lcm_params-dsi-CLK_HS_EXIT;
		lcm_params-dsi-CLK_HS_POST;
		lcm_params-dsi-CLK_HS_PRPR;
		lcm_params-dsi-CLK_TRAIL;
		lcm_params-dsi-CLK_ZERO;
		lcm_params-dsi-CONT_DET;
		lcm_params-dsi-DA_HS_EXIT;
		lcm_params-dsi-DSI_RMEM_CONTI;
		lcm_params-dsi-DSI_WMEM_CONTI;
		lcm_params-dsi-HS_PRPR;
		lcm_params-dsi-HS_TRAIL;
		lcm_params-dsi-LPX;
		lcm_params-dsi-LPX_WAIT;
		lcm_params-dsi-TA_GET;
		lcm_params-dsi-TA_GO;
		lcm_params-dsi-TA_SACK;
		lcm_params-dsi-TA_SURE;
		lcm_params-dsi-VC_NUM;
		lcm_params-dsi-ZERO;
		lcm_params-dsi-clk_lp_per_line_enable = <0x00>;
		lcm_params-dsi-compatibility_for_nvk;
		lcm_params-dsi-cont_clock;
		lcm_params-dsi-customization_esd_check_enable = <0x00>;
		lcm_params-dsi-data_format = <0x02 0x00 0x00 0x02>;
		lcm_params-dsi-dsi_clock;
		lcm_params-dsi-dual_dsi_type;
		lcm_params-dsi-edp_panel;
		lcm_params-dsi-esd_check_enable = <0x01>;
		lcm_params-dsi-fbk_div;
		lcm_params-dsi-fbk_sel;
		lcm_params-dsi-horizontal_active_pixel = <0x438>;
		lcm_params-dsi-horizontal_backporch = <0x3c>;
		lcm_params-dsi-horizontal_backporch_word_count;
		lcm_params-dsi-horizontal_backportch_byte;
		lcm_params-dsi-horizontal_blanking_pixel;
		lcm_params-dsi-horizontal_bllp;
		lcm_params-dsi-horizontal_frontporch = <0x64>;
		lcm_params-dsi-horizontal_frontporch_byte;
		lcm_params-dsi-horizontal_frontporch_word_count;
		lcm_params-dsi-horizontal_sync_active = <0x0a>;
		lcm_params-dsi-horizontal_sync_active_byte;
		lcm_params-dsi-horizontal_sync_active_word_count;
		lcm_params-dsi-intermediat_buffer_num;
		lcm_params-dsi-lane_num = <0x04>;
		lcm_params-dsi-lane_swap0;
		lcm_params-dsi-lane_swap1;
		lcm_params-dsi-lane_swap_en;
		lcm_params-dsi-lcm_esd_check_table0 = <0x0a 0x01 0x1c 0x00>;
		lcm_params-dsi-lcm_esd_check_table1;
		lcm_params-dsi-lcm_esd_check_table2;
		lcm_params-dsi-lcm_ext_te_enable;
		lcm_params-dsi-lcm_ext_te_monitor;
		lcm_params-dsi-lcm_int_te_monitor;
		lcm_params-dsi-lcm_int_te_period;
		lcm_params-dsi-line_byte;
		lcm_params-dsi-mode = <0x00>;
		lcm_params-dsi-noncont_clock;
		lcm_params-dsi-noncont_clock_period;
		lcm_params-dsi-packet_size = <0x100>;
		lcm_params-dsi-pll_clock = <0x1c2>;
		lcm_params-dsi-pll_div1;
		lcm_params-dsi-pll_div2;
		lcm_params-dsi-pll_select;
		lcm_params-dsi-ps = <0x02>;
		lcm_params-dsi-rg_bic;
		lcm_params-dsi-rg_bir;
		lcm_params-dsi-rg_bp;
		lcm_params-dsi-rgb_byte;
		lcm_params-dsi-ssc_disable;
		lcm_params-dsi-ssc_range;
		lcm_params-dsi-switch_mode = <0x02>;
		lcm_params-dsi-switch_mode_enable = <0x00>;
		lcm_params-dsi-ufoe_enable;
		lcm_params-dsi-ufoe_params;
		lcm_params-dsi-vertical_active_line = <0x780>;
		lcm_params-dsi-vertical_backporch = <0x08>;
		lcm_params-dsi-vertical_frontporch = <0x0a>;
		lcm_params-dsi-vertical_frontporch_for_low_power;
		lcm_params-dsi-vertical_sync_active = <0x02>;
		lcm_params-dsi-vertical_vfp_lp;
		lcm_params-dsi-word_count;
		lcm_params-io_select_mode;
		lcm_params-od_table;
		lcm_params-od_table_size;
		lcm_params-physical_height;
		lcm_params-physical_width;
		lcm_params-resolution = <0x438 0x780>;
		lcm_params-types = <0x02 0x00 0x00 0x00>;
	};

	led@0 {
		compatible = "mediatek,red";
		data = <0x01>;
		led_mode = <0x00>;
		pwm_config = <0x00 0x00 0x00 0x00 0x00>;
	};

	led@1 {
		compatible = "mediatek,green";
		data = <0x01>;
		led_mode = <0x00>;
		pwm_config = <0x00 0x00 0x00 0x00 0x00>;
	};

	led@2 {
		compatible = "mediatek,blue";
		data = <0x01>;
		led_mode = <0x00>;
		pwm_config = <0x00 0x00 0x00 0x00 0x00>;
	};

	led@3 {
		compatible = "mediatek,jogball-backlight";
		data = <0x01>;
		led_mode = <0x00>;
		pwm_config = <0x00 0x00 0x00 0x00 0x00>;
	};

	led@4 {
		compatible = "mediatek,keyboard-backlight";
		data = <0x01>;
		led_mode = <0x00>;
		pwm_config = <0x00 0x00 0x00 0x00 0x00>;
	};

	led@5 {
		compatible = "mediatek,button-backlight";
		data = <0x01>;
		led_mode = <0x00>;
		pwm_config = <0x00 0x00 0x00 0x00 0x00>;
	};

	led@6 {
		compatible = "mediatek,lcd-backlight";
		data = <0x01>;
		led_mode = <0x05>;
		pwm_config = <0x00 0x00 0x00 0x00 0x00>;
	};

	m_acc_pl@0 {
		compatible = "mediatek,m_acc_pl";
	};

	m_alsps_pl@0 {
		compatible = "mediatek,m_alsps_pl";
	};

	m_baro_pl@0 {
		compatible = "mediatek,m_baro_pl";
	};

	m_batch_pl@0 {
		compatible = "mediatek,m_batch_pl";
	};

	m_gyro_pl@0 {
		compatible = "mediatek,m_gyro_pl";
	};

	m_mag_pl@0 {
		compatible = "mediatek,m_mag_pl";
	};

	memory@00000000 {
		device_type = "memory";
		reg = <0x00 0x40000000 0x00 0x3f000000>;
	};

	msensor@0 {
		compatible = "mediatek,msensor";
	};

	mt8193ckgen@0 {
		bus_switch_pin = <0x09 0x00 0x00>;
		compatible = "mediatek,mt8193-ckgen";
		pinctrl-0 = <0x7e>;
		pinctrl-1 = <0x7f>;
		pinctrl-2 = <0x80>;
		pinctrl-names = "default\0bus_switch_gpio\0bus_switch_dpi";
		status = "okay";
	};

	mtk-msdc.0 {
		#address-cells = <0x01>;
		#size-cells = <0x01>;
		compatible = "simple-bus";
		ranges = <0x00 0x00 0x00 0xffffffff>;

		default {
			compatible = "mediatek, msdc1_ins-eint";
			debounce = <0x03 0x3e8>;
			interrupt-parent = <0x0b>;
			interrupts = <0x03 0x08>;
			status = "okay";
		};

		msdc0@11230000 {
			bootable;
			bus-width = <0x08>;
			cap-mmc-highspeed;
			clk_src = [02];
			compatible = "mediatek,mt6753-mmc";
			host_function = [00];
			interrupts = <0x00 0x4f 0x08>;
			max-frequency = <0xbebc200>;
			mmc-ddr-1_8v;
			mmc-hs200-1_8v;
			mmc-hs400-1_8v;
			msdc-sys-suspend;
			non-removable;
			pinctl = <0x02>;
			reg = <0x11230000 0x10000 0x10000e84 0x02>;
			register_setting = <0x03>;
			status = "okay";
		};

		msdc1@11240000 {
			bus-width = <0x04>;
			cap-sd-highspeed;
			cd-gpios = <0x09 0x03 0x00>;
			cd_level = [01];
			clk_src = [02];
			compatible = "mediatek,mt6753-mmc";
			host_function = [01];
			interrupts = <0x00 0x50 0x08>;
			max-frequency = <0xbebc200>;
			msdc-sys-suspend;
			pinctl = <0x04>;
			pinctl_ddr50 = <0x07>;
			pinctl_sdr104 = <0x05>;
			pinctl_sdr50 = <0x06>;
			reg = <0x11240000 0x10000 0x10000e84 0x02>;
			register_setting = <0x08>;
			sd-uhs-ddr50;
			sd-uhs-sdr104;
			sd-uhs-sdr12;
			sd-uhs-sdr25;
			sd-uhs-sdr50;
			status = "okay";
		};

		msdc2@11250000 {
			clock-names = "MSDC2-CLOCK";
			clocks = <0x0a 0x10>;
			compatible = "mediatek,mt6735-mmc";
			interrupts = <0x00 0x51 0x08>;
			reg = <0x11250000 0x10000 0x10000e84 0x02>;
			status = "disabled";
		};

		msdc3@11260000 {
			clock-names = "MSDC3-CLOCK";
			clocks = <0x0a 0x11>;
			compatible = "mediatek,mt6735-mmc";
			interrupts = <0x00 0x52 0x08>;
			reg = <0x11260000 0x10000 0x10000e84 0x02>;
			status = "disabled";
		};
	};

	multibridge@0 {
		compatible = "mediatek,multibridge";
	};

	orientation@0 {
		compatible = "mediatek,orientation";
	};

	psci {
		affinity_info = <0x84000004>;
		compatible = "arm,psci";
		cpu_off = <0x84000002>;
		cpu_on = <0x84000003>;
		cpu_suspend = <0x84000001>;
		method = "smc";
	};

	reserved-memory {
		#address-cells = <0x02>;
		#size-cells = <0x02>;
		ranges;

		atf-reserved-memory@43000000 {
			compatible = "mediatek,mt6735-atf-reserved-memory\0mediatek,mt6735m-atf-reserved-memory\0mediatek,mt6753-atf-reserved-memory";
			no-map;
			reg = <0x00 0x43000000 0x00 0x30000>;
		};

		consys-reserve-memory {
			alignment = <0x00 0x200000>;
			compatible = "mediatek,consys-reserve-memory";
			no-map;
			size = <0x00 0x100000>;
		};

		minirdump-reserved-memory@43ff0000 {
			compatible = "mediatek, minirdump";
			reg = <0x00 0x43ff0000 0x00 0x10000>;
		};

		pstore-reserved-memory@43f10000 {
			compatible = "mediatek,pstore";
			reg = <0x00 0x43f10000 0x00 0xe0000>;
		};

		ram_console-reserved-memory@43f00000 {
			compatible = "mediatek,ram_console";
			reg = <0x00 0x43f00000 0x00 0x10000>;
		};

		reserve-memory-ccci_md1 {
			alignment = <0x00 0x2000000>;
			alloc-ranges = <0x00 0x40000000 0x00 0xc0000000>;
			compatible = "mediatek,reserve-memory-ccci_md1";
			no-map;
			size = <0x00 0x3810000>;
		};
	};

	rf_clock_buffer {
		compatible = "mediatek,rf_clock_buffer";
		mediatek,clkbuf-config = <0x02 0x01 0x01 0x01>;
		mediatek,clkbuf-quantity = <0x04>;
		status = "okay";
	};

	soc {
		#address-cells = <0x01>;
		#size-cells = <0x01>;
		compatible = "simple-bus";
		ranges;

		SENINF_TOP@0x15008000 {
			compatible = "mediatek,SENINF_TOP";
			interrupts = <0x00 0xb6 0x08>;
			reg = <0x15008000 0x1000>;
		};

		THERM_CTRL@0x1100B000 {
			compatible = "mediatek,THERM_CTRL";
			interrupts = <0x00 0x4e 0x08>;
			reg = <0x1100b000 0x1000>;
		};

		adc_hw@11001000 {
			clock-names = "auxadc-main";
			clocks = <0x0a 0x1c>;
			compatible = "mediatek,mt6735-auxadc";
			interrupts = <0x00 0x4c 0x02>;
			reg = <0x11001000 0x1000>;

			adc_channel@ {
				compatible = "mediatek,adc_channel";
				mediatek,adc_fdd_rf_params_dynamic_custom_ch = <0x0c>;
				mediatek,temperature0 = <0x00>;
				mediatek,temperature1 = <0x01>;
				status = "okay";
			};
		};

		als {
			compatible = "mediatek, als-eint";
			debounce = <0x02 0x00>;
			interrupt-parent = <0x0b>;
			interrupts = <0x02 0x02>;
			status = "okay";
		};

		apmixedsys@0x10209000 {
			#clock-cells = <0x01>;
			compatible = "mediatek,mt6735-apmixedsys";
			reg = <0x10209000 0x1000>;
		};

		apuart0@11002000 {
			cell-index = <0x00>;
			clock-div = <0x01>;
			clock-frequency = <0x18cba80>;
			clock-names = "uart0-main\0uart-apdma";
			clocks = <0x0a 0x12 0x0a 0x0d>;
			compatible = "mediatek,mt6735-uart";
			interrupts = <0x00 0x5b 0x08 0x00 0x67 0x08 0x00 0x68 0x08>;
			reg = <0x11002000 0x1000 0x11000400 0x1000 0x11000480 0x80>;
		};

		apuart1@11003000 {
			cell-index = <0x01>;
			clock-div = <0x01>;
			clock-frequency = <0x18cba80>;
			clock-names = "uart1-main";
			clocks = <0x0a 0x13>;
			compatible = "mediatek,mt6735-uart";
			interrupts = <0x00 0x5c 0x08 0x00 0x69 0x08 0x00 0x6a 0x08>;
			reg = <0x11003000 0x1000 0x11000500 0x80 0x11000580 0x80>;
		};

		apuart2@11004000 {
			cell-index = <0x02>;
			clock-div = <0x01>;
			clock-frequency = <0x18cba80>;
			clock-names = "uart2-main";
			clocks = <0x0a 0x14>;
			compatible = "mediatek,mt6735-uart";
			interrupts = <0x00 0x5d 0x08 0x00 0x6b 0x08 0x00 0x6c 0x08>;
			reg = <0x11004000 0x1000 0x11000600 0x80 0x11000680 0x80>;
		};

		apuart3@11005000 {
			cell-index = <0x03>;
			clock-div = <0x01>;
			clock-frequency = <0x18cba80>;
			clock-names = "uart3-main";
			clocks = <0x0a 0x15>;
			compatible = "mediatek,mt6735-uart";
			interrupts = <0x00 0x5e 0x08 0x00 0x6d 0x08 0x00 0x6e 0x08>;
			reg = <0x11005000 0x1000 0x11000700 0x80 0x11000780 0x80>;
		};

		apuart4@1100d000 {
			cell-index = <0x04>;
			clock-div = <0x01>;
			clock-frequency = <0x18cba80>;
			clock-names = "uart4-main";
			clocks = <0x0a 0x16>;
			compatible = "mediatek,mt6735-uart";
			interrupts = <0x00 0x5f 0x08 0x00 0x6f 0x08 0x00 0x70 0x08>;
			reg = <0x1100d000 0x1000 0x11000800 0x80 0x11000880 0x80>;
		};

		apxgpt@10004000 {
			clock-frequency = <0xc65d40>;
			compatible = "mediatek,mt6735-apxgpt";
			interrupts = <0x00 0x98 0x08>;
			reg = <0x10004000 0x1000>;
		};

		audiosys@11220000 {
			#clock-cells = <0x01>;
			compatible = "mediatek,mt6735-audiosys";
			reg = <0x11220000 0x10000>;
		};

		btif@1100c000 {
			compatible = "mediatek,btif";
			interrupts = <0x00 0x5a 0x08>;
			reg = <0x1100c000 0x1000>;
		};

		btif_rx@11000980 {
			compatible = "mediatek,btif_rx";
			interrupts = <0x00 0x72 0x08>;
			reg = <0x11000980 0x80>;
		};

		btif_tx@11000900 {
			compatible = "mediatek,btif_tx";
			interrupts = <0x00 0x71 0x08>;
			reg = <0x11000900 0x80>;
		};

		chipid@08000000 {
			compatible = "mediatek,chipid";
			reg = <0x8000000 0x04 0x8000004 0x04 0x8000008 0x04 0x800000c 0x04>;
		};

		consys@18070000 {
			compatible = "mediatek,mt6753-consys\0mediatek,mt6735-consys";
			interrupts = <0x00 0xe5 0x08 0x00 0xe3 0x08>;
			pinctrl-0 = <0x2e>;
			pinctrl-1 = <0x2f>;
			pinctrl-2 = <0x30>;
			pinctrl-3 = <0x31>;
			pinctrl-names = "default\0gps_lna_state_init\0gps_lna_state_oh\0gps_lna_state_ol";
			reg = <0x18070000 0x200 0x10212000 0x100 0x10000000 0x2000 0x10006000 0x1000>;
			status = "okay";
		};

		cpuxgpt@10200000 {
			compatible = "mediatek,mt6735-cpuxgpt";
			interrupts = <0x00 0x40 0x04 0x00 0x41 0x04 0x00 0x42 0x04 0x00 0x43 0x04 0x00 0x44 0x04 0x00 0x45 0x04 0x00 0x46 0x04 0x00 0x47 0x04>;
			reg = <0x10200000 0x1000>;
		};

		ddrphy@10213000 {
			compatible = "mediatek,mt6735-ddrphy";
			reg = <0x10213000 0x1000>;
		};

		dramc@10214000 {
			clock-names = "infra-cqdma";
			clocks = <0x16 0x02>;
			compatible = "mediatek,mt6735-dramc";
			reg = <0x10214000 0x1000>;
		};

		dramc_nao@1020e000 {
			compatible = "mediatek,mt6735-dramc_nao";
			reg = <0x1020e000 0x1000>;
		};

		dsi_te {
			compatible = "mediatek, dsi_te_1-eint";
			status = "disabled";
		};

		ext_buck_oc {
			compatible = "mediatek, ext_buck_oc-eint";
			debounce = <0x4e 0x00>;
			interrupt-parent = <0x0b>;
			interrupts = <0x4e 0x04>;
			status = "okay";
		};

		fdvt@1500b000 {
			clock-names = "FD-SCP_SYS_DIS\0FD-SCP_SYS_ISP\0FD-MM_DISP0_SMI_COMMON\0FD-IMG_IMAGE_FD";
			clocks = <0x2d 0x04 0x2d 0x06 0x29 0x01 0x32 0x08>;
			compatible = "mediatek,fdvt";
			interrupts = <0x00 0xd0 0x08>;
			reg = <0x1500b000 0x1000>;
		};

		gce@10217000 {
			apxgpt2_count = <0x10004028>;
			audio_base = <0x11220000 0x12 0xffff0000>;
			buf_underrun_event_0 = <0x32>;
			buf_underrun_event_1 = <0x33>;
			camsv_1_pass1_done = <0x47>;
			camsv_2_pass1_done = <0x46>;
			compatible = "mediatek,gce";
			conn_peri_base = <0x18000000 0x07 0xffff0000>;
			disp_aal_frame_done = <0x21>;
			disp_aal_sof = <0x0d>;
			disp_ccorr_frame_done = <0x1f>;
			disp_ccorr_sof = <0x0b>;
			disp_color_frame_done = <0x20>;
			disp_color_sof = <0x0c>;
			disp_dither_base = <0x14010000 0x02 0xffff0000>;
			disp_dither_frame_done = <0x23>;
			disp_dither_sof = <0x0f>;
			disp_dpi0_frame_done = <0x26>;
			disp_dsi0_frame_done = <0x27>;
			disp_gamma_frame_done = <0x22>;
			disp_gamma_sof = <0x0e>;
			disp_mutex_reg = <0x14015000 0x1000>;
			disp_od_frame_done = <0x25>;
			disp_od_sof = <0x12>;
			disp_ovl0_frame_done = <0x1a>;
			disp_ovl0_sof = <0x06>;
			disp_ovl1_frame_done = <0x1b>;
			disp_ovl1_sof = <0x07>;
			disp_pwm0_sof = <0x11>;
			disp_rdma0_frame_done = <0x1c>;
			disp_rdma0_sof = <0x08>;
			disp_rdma1_frame_done = <0x1d>;
			disp_rdma1_sof = <0x09>;
			disp_wdma0_frame_done = <0x1e>;
			disp_wdma0_sof = <0x0a>;
			dsi0_te_event = <0x34>;
			g3d_config_base = <0x13000000 0x00 0xffff0000>;
			gcpu_base = <0x10210000 0x0f 0xffff0000>;
			imgsys_base = <0x15000000 0x04 0xffff0000>;
			infra_na3_base = <0x10030000 0x0b 0xffff0000>;
			infra_na4_base = <0x10040000 0x0c 0xffff0000>;
			interrupts = <0x00 0x97 0x08 0x00 0x94 0x08>;
			isp_frame_done_p1_0 = <0x45>;
			isp_frame_done_p1_1 = <0x44>;
			isp_frame_done_p2_0 = <0x43>;
			isp_frame_done_p2_1 = <0x42>;
			isp_frame_done_p2_2 = <0x41>;
			jpgdec_done = <0x83>;
			jpgenc_done = <0x82>;
			kp_base = <0x10010000 0x09 0xffff0000>;
			mcucfg_base = <0x10200000 0x0e 0xffff0000>;
			mdp_rdma0_frame_done = <0x13>;
			mdp_rdma0_sof = <0x00>;
			mdp_rsz0_frame_done = <0x14>;
			mdp_rsz0_sof = <0x01>;
			mdp_rsz1_frame_done = <0x15>;
			mdp_rsz1_sof = <0x02>;
			mdp_tdshp_frame_done = <0x16>;
			mdp_tdshp_sof = <0x03>;
			mdp_wdma_frame_done = <0x17>;
			mdp_wdma_sof = <0x04>;
			mdp_wrot_read_frame_done = <0x19>;
			mdp_wrot_sof = <0x05>;
			mdp_wrot_write_frame_done = <0x18>;
			mm_na_base = <0x14020000 0x03 0xffff0000>;
			mmsys_config_base = <0x14000000 0x01 0xffff0000>;
			msdc0_base = <0x11230000 0x13 0xffff0000>;
			msdc1_base = <0x11240000 0x14 0xffff0000>;
			msdc2_base = <0x11250000 0x15 0xffff0000>;
			msdc3_base = <0x11260000 0x16 0xffff0000>;
			pwm_sw_base = <0x1100e000 0x63 0xfffff000>;
			reg = <0x10217000 0x1000>;
			scp_base = <0x10050000 0x0d 0xffff0000>;
			scp_sram_base = <0x10020000 0x0a 0xffff0000>;
			seninf_cam0_fifo_full = <0x49>;
			seninf_cam1_2_3_fifo_full = <0x48>;
			stream_done_0 = <0x28>;
			stream_done_1 = <0x29>;
			stream_done_2 = <0x2a>;
			stream_done_3 = <0x2b>;
			stream_done_4 = <0x2c>;
			stream_done_5 = <0x2d>;
			stream_done_6 = <0x2e>;
			stream_done_7 = <0x2f>;
			stream_done_8 = <0x30>;
			stream_done_9 = <0x31>;
			topckgen_base = <0x10000000 0x08 0xffff0000>;
			usb0_base = <0x11200000 0x10 0xffff0000>;
			usb_sif_base = <0x11210000 0x11 0xffff0000>;
			vdec_gcon_base = <0x16000000 0x05 0xffff0000>;
			venc_128byte_cnt_done = <0x85>;
			venc_done = <0x81>;
			venc_gcon_base = <0x17000000 0x06 0xffff0000>;
			venc_mb_done = <0x84>;
		};

		gpio {
			GPIO_SIM1_HOT_PLUG = <0x03>;
			GPIO_SIM1_SCLK = <0xa3>;
			GPIO_SIM1_SIO = <0xa5>;
			GPIO_SIM1_SRST = <0xa4>;
			GPIO_SIM2_SCLK = <0xa0>;
			GPIO_SIM2_SIO = <0xa2>;
			GPIO_SIM2_SRST = <0xa1>;
			compatible = "mediatek,gpio_usage_mapping";
		};

		gpio@10211000 {
			compatible = "mediatek,gpio";
			reg = <0x10211000 0x1000>;
		};

		gse_1 {
			compatible = "mediatek, gse_1-eint";
			debounce = <0x07 0x00>;
			interrupt-parent = <0x0b>;
			interrupts = <0x07 0x04>;
			status = "okay";
		};

		hacc@10008000 {
			compatible = "mediatek,hacc";
			interrupts = <0x00 0xae 0x08>;
			reg = <0x10008000 0x1000>;
		};

		imgsys@0x15000000 {
			#clock-cells = <0x01>;
			compatible = "mediatek,mt6735-imgsys";
			linux,phandle = <0x32>;
			phandle = <0x32>;
			reg = <0x15000000 0x1000>;
		};

		infrasys@0x10000000 {
			#clock-cells = <0x01>;
			compatible = "mediatek,mt6735-infrasys";
			linux,phandle = <0x16>;
			phandle = <0x16>;
			reg = <0x10000000 0x1000>;
		};

		irtx@11011000 {
			clock-div = <0x01>;
			clock-frequency = <0x18cba80>;
			clock-names = "clk-irtx-main";
			clocks = <0x0a 0x1e>;
			compatible = "mediatek,irtx";
			interrupts = <0x00 0x7c 0x04>;
			pwm_ch = <0x00>;
			reg = <0x11011000 0x1000>;
		};

		ispsys@15000000 {
			compatible = "mediatek,mt6735-ispsys";
			interrupts = <0x00 0xb7 0x08 0x00 0xb8 0x08 0x00 0xb9 0x08 0x00 0xce 0x08 0x00 0xcf 0x08>;
			reg = <0x15004000 0x9000 0x1500d000 0x1000 0x15000000 0x10000 0x10215000 0x3000 0x10211000 0x1000>;
		};

		jpgdec@17004000 {
			clock-names = "disp-mtcmos\0disp-smi\0venc-mtcmos\0venc-larb\0venc-jpgdec";
			clocks = <0x2d 0x04 0x29 0x01 0x2d 0x08 0x2b 0x01 0x2b 0x04>;
			compatible = "mediatek,jpgdec";
			interrupts = <0x00 0xd1 0x08>;
			reg = <0x17004000 0x1000>;
		};

		jpgenc@17003000 {
			clock-names = "disp-mtcmos\0disp-smi\0venc-mtcmos\0venc-larb\0venc-jpgenc";
			clocks = <0x2d 0x04 0x29 0x01 0x2d 0x08 0x2b 0x01 0x2b 0x03>;
			compatible = "mediatek,jpgenc";
			interrupts = <0x00 0xb5 0x08>;
			reg = <0x17003000 0x1000>;
		};

		kd_camera_hw1@15008000 {
			compatible = "mediatek,camera_hw";
			pinctrl-0 = <0x37>;
			pinctrl-1 = <0x38>;
			pinctrl-10 = <0x41>;
			pinctrl-11 = <0x42>;
			pinctrl-12 = <0x43>;
			pinctrl-13 = <0x44>;
			pinctrl-14 = <0x45>;
			pinctrl-2 = <0x39>;
			pinctrl-3 = <0x3a>;
			pinctrl-4 = <0x3b>;
			pinctrl-5 = <0x3c>;
			pinctrl-6 = <0x3d>;
			pinctrl-7 = <0x3e>;
			pinctrl-8 = <0x3f>;
			pinctrl-9 = <0x40>;
			pinctrl-names = "default\0cam0_rst0\0cam0_rst1\0cam0_pnd0\0cam0_pnd1\0cam1_rst0\0cam1_rst1\0cam1_pnd0\0cam1_pnd1\0cam_ldo0_0\0cam_ldo0_1\0cam_ldo1_0\0cam_ldo1_1\0flashlight_enable_0\0flashlight_enable_1";
			reg = <0x15008000 0x1000>;
			status = "okay";
			vcama-supply = <0x33>;
			vcama_main2-supply = <0x33>;
			vcama_sub-supply = <0x33>;
			vcamaf-supply = <0x35>;
			vcamaf_main2-supply = <0x35>;
			vcamaf_sub-supply = <0x35>;
			vcamd-supply = <0x34>;
			vcamd_main2-supply = <0x34>;
			vcamd_sub-supply = <0x34>;
			vcamio-supply = <0x36>;
			vcamio_main2-supply = <0x36>;
			vcamio_sub-supply = <0x36>;
		};

		kd_camera_hw2@15008000 {
			compatible = "mediatek,camera_hw2";
			reg = <0x15008000 0x1000>;
		};

		keypad@10003000 {
			compatible = "mediatek,mt6735-keypad";
			interrupts = <0x00 0xa4 0x02>;
			mediatek,kpd-hw-dl-key0 = <0x01>;
			mediatek,kpd-hw-dl-key1 = <0x11>;
			mediatek,kpd-hw-dl-key2 = <0x08>;
			mediatek,kpd-hw-factory-key = <0x11>;
			mediatek,kpd-hw-init-map = <0x00 0x73 0x00 0x00 0x00 0x00 0x00 0x00 0x00 0x00 0x00 0x00 0x00 0x00 0x00 0x00 0x00 0x00 0x00 0x00 0x00 0x00 0x00 0x00 0x00 0x00 0x00 0x00 0x00 0x00 0x00 0x00 0x00 0x00 0x00 0x00 0x00 0x00 0x00 0x00 0x00 0x00 0x00 0x00 0x00 0x00 0x00 0x00 0x00 0x00 0x00 0x00 0x00 0x00 0x00 0x00 0x00 0x00 0x00 0x00 0x00 0x00 0x00 0x00 0x00 0x00 0x00 0x00 0x00 0x00 0x00 0x00>;
			mediatek,kpd-hw-map-num = <0x48>;
			mediatek,kpd-hw-pwrkey = <0x08>;
			mediatek,kpd-hw-recovery-key = <0x01>;
			mediatek,kpd-hw-rstkey = <0x11>;
			mediatek,kpd-key-debounce = <0x400>;
			mediatek,kpd-pwkey-gpio-din = <0x00>;
			mediatek,kpd-pwrkey-eint-gpio = <0x00>;
			mediatek,kpd-sw-pwrkey = <0x74>;
			mediatek,kpd-sw-rstkey = <0x72>;
			mediatek,kpd-use-extend-type = <0x00>;
			reg = <0x10003000 0x1000>;
			status = "okay";
		};

		mdp_rdma@14001000 {
			compatible = "mediatek,mdp_rdma";
			interrupts = <0x00 0xbb 0x08>;
			reg = <0x14001000 0x1000>;
		};

		mdp_rsz0@14002000 {
			compatible = "mediatek,mdp_rsz0";
			interrupts = <0x00 0xbc 0x08>;
			reg = <0x14002000 0x1000>;
		};

		mdp_rsz1@14003000 {
			compatible = "mediatek,mdp_rsz1";
			interrupts = <0x00 0xbd 0x08>;
			reg = <0x14003000 0x1000>;
		};

		mdp_tdshp@14006000 {
			compatible = "mediatek,mdp_tdshp";
			interrupts = <0x00 0xbe 0x08>;
			reg = <0x14006000 0x1000>;
		};

		mdp_wdma@14004000 {
			compatible = "mediatek,mdp_wdma";
			interrupts = <0x00 0xbf 0x08>;
			reg = <0x14004000 0x1000>;
		};

		mdp_wrot@14005000 {
			compatible = "mediatek,mdp_wrot";
			interrupts = <0x00 0xc0 0x08>;
			reg = <0x14005000 0x1000>;
		};

		met_smi@14017000 {
			compatible = "mediatek,met_smi";
			reg = <0x14017000 0x1000 0x14016000 0x1000 0x16010000 0x1000 0x15001000 0x1000 0x17001000 0x1000>;
		};

		mfgsys@0x13000000 {
			#clock-cells = <0x01>;
			compatible = "mediatek,mt6735-mfgsys";
			linux,phandle = <0x78>;
			phandle = <0x78>;
			reg = <0x13000000 0x1000>;
		};

		mmsys@0x14000000 {
			#clock-cells = <0x01>;
			compatible = "mediatek,mt6735-mmsys";
			linux,phandle = <0x29>;
			phandle = <0x29>;
			reg = <0x14000000 0x1000>;
		};

		mmsys_config@14000000 {
			compatible = "mediatek,mmsys_config";
			interrupts = <0x00 0xcd 0x08>;
			reg = <0x14000000 0x1000>;
		};

		mt_pmic_regulator {
			compatible = "mediatek,mt_pmic";

			buck_regulators {
				compatible = "mediatek,mt_pmic_buck_regulators";

				buck_vcore1 {
					regulator-always-on;
					regulator-boot-on;
					regulator-enable-ramp-delay = <0xb4>;
					regulator-max-microvolt = <0x154456>;
					regulator-min-microvolt = <0x927c0>;
					regulator-name = "vcore1";
					regulator-ramp-delay = <0x186a>;
				};

				buck_vlte {
					regulator-always-on;
					regulator-boot-on;
					regulator-enable-ramp-delay = <0xb4>;
					regulator-max-microvolt = <0x154456>;
					regulator-min-microvolt = <0x927c0>;
					regulator-name = "vlte";
					regulator-ramp-delay = <0x186a>;
				};

				buck_vpa {
					regulator-enable-ramp-delay = <0xb4>;
					regulator-max-microvolt = <0x37b1d0>;
					regulator-min-microvolt = <0x7a120>;
					regulator-name = "vpa";
					regulator-ramp-delay = <0xc350>;
				};

				buck_vproc {
					regulator-always-on;
					regulator-boot-on;
					regulator-enable-ramp-delay = <0xb4>;
					regulator-max-microvolt = <0x154456>;
					regulator-min-microvolt = <0x927c0>;
					regulator-name = "vproc";
					regulator-ramp-delay = <0x186a>;
				};

				buck_vsys22 {
					regulator-always-on;
					regulator-boot-on;
					regulator-enable-ramp-delay = <0xb4>;
					regulator-max-microvolt = <0x1e6c16>;
					regulator-min-microvolt = <0x124f80>;
					regulator-name = "vsys22";
					regulator-ramp-delay = <0x186a>;
				};
			};

			ldo_regulators {
				compatible = "mediatek,mt_pmic_ldo_regulators";

				ldo_vaud28 {
					linux,phandle = <0x1a>;
					phandle = <0x1a>;
					regulator-boot-on;
					regulator-enable-ramp-delay = <0x108>;
					regulator-max-microvolt = <0x2ab980>;
					regulator-min-microvolt = <0x2ab980>;
					regulator-name = "vaud28";
				};

				ldo_vaux18 {
					linux,phandle = <0x17>;
					phandle = <0x17>;
					regulator-boot-on;
					regulator-enable-ramp-delay = <0x108>;
					regulator-max-microvolt = <0x1b7740>;
					regulator-min-microvolt = <0x1b7740>;
					regulator-name = "vaux18";
				};

				ldo_vcama {
					linux,phandle = <0x33>;
					phandle = <0x33>;
					regulator-default-on = <0x00>;
					regulator-enable-ramp-delay = <0x108>;
					regulator-max-microvolt = <0x2ab980>;
					regulator-min-microvolt = <0x16e360>;
					regulator-name = "vcama";
					status = "okay";
				};

				ldo_vcamaf {
					linux,phandle = <0x35>;
					phandle = <0x35>;
					regulator-default-on = <0x00>;
					regulator-enable-ramp-delay = <0x108>;
					regulator-max-microvolt = <0x325aa0>;
					regulator-min-microvolt = <0x124f80>;
					regulator-name = "vcamaf";
					status = "okay";
				};

				ldo_vcamd {
					linux,phandle = <0x34>;
					phandle = <0x34>;
					regulator-default-on = <0x00>;
					regulator-enable-ramp-delay = <0x108>;
					regulator-max-microvolt = <0x16e360>;
					regulator-min-microvolt = <0xdbba0>;
					regulator-name = "vcamd";
					status = "okay";
				};

				ldo_vcamio {
					linux,phandle = <0x36>;
					phandle = <0x36>;
					regulator-default-on = <0x00>;
					regulator-enable-ramp-delay = <0xdc>;
					regulator-max-microvolt = <0x1b7740>;
					regulator-min-microvolt = <0x124f80>;
					regulator-name = "vcamio";
					status = "okay";
				};

				ldo_vcn18 {
					regulator-enable-ramp-delay = <0x2c>;
					regulator-max-microvolt = <0x1b7740>;
					regulator-min-microvolt = <0x1b7740>;
					regulator-name = "vcn18";
				};

				ldo_vcn28 {
					regulator-enable-ramp-delay = <0x108>;
					regulator-max-microvolt = <0x2ab980>;
					regulator-min-microvolt = <0x2ab980>;
					regulator-name = "vcn28";
				};

				ldo_vcn33_bt {
					regulator-enable-ramp-delay = <0x108>;
					regulator-max-microvolt = <0x36ee80>;
					regulator-min-microvolt = <0x325aa0>;
					regulator-name = "vcn33_bt";
				};

				ldo_vcn33_wifi {
					regulator-enable-ramp-delay = <0x108>;
					regulator-max-microvolt = <0x36ee80>;
					regulator-min-microvolt = <0x325aa0>;
					regulator-name = "vcn33_wifi";
				};

				ldo_vefuse {
					linux,phandle = <0x1b>;
					phandle = <0x1b>;
					regulator-enable-ramp-delay = <0x108>;
					regulator-max-microvolt = <0x2191c0>;
					regulator-min-microvolt = <0x1b7740>;
					regulator-name = "vefuse";
				};

				ldo_vemc_3v3 {
					linux,phandle = <0x1e>;
					phandle = <0x1e>;
					regulator-boot-on;
					regulator-enable-ramp-delay = <0x108>;
					regulator-max-microvolt = <0x325aa0>;
					regulator-min-microvolt = <0x1b7740>;
					regulator-name = "vemc_3v3";
				};

				ldo_vgp1 {
					linux,phandle = <0x66>;
					phandle = <0x66>;
					regulator-default-on = <0x00>;
					regulator-enable-ramp-delay = <0x108>;
					regulator-max-microvolt = <0x325aa0>;
					regulator-min-microvolt = <0x124f80>;
					regulator-name = "vgp1";
					status = "okay";
				};

				ldo_vibr {
					linux,phandle = <0x23>;
					phandle = <0x23>;
					regulator-default-on = <0x00>;
					regulator-enable-ramp-delay = <0x2c>;
					regulator-max-microvolt = <0x325aa0>;
					regulator-min-microvolt = <0x124f80>;
					regulator-name = "vibr";
					status = "okay";
				};

				ldo_vio18 {
					linux,phandle = <0x26>;
					phandle = <0x26>;
					regulator-boot-on;
					regulator-enable-ramp-delay = <0x108>;
					regulator-max-microvolt = <0x1b7740>;
					regulator-min-microvolt = <0x1b7740>;
					regulator-name = "vio18";
				};

				ldo_vio28 {
					linux,phandle = <0x22>;
					phandle = <0x22>;
					regulator-boot-on;
					regulator-enable-ramp-delay = <0x108>;
					regulator-max-microvolt = <0x2ab980>;
					regulator-min-microvolt = <0x2ab980>;
					regulator-name = "vio28";
				};

				ldo_vm {
					linux,phandle = <0x28>;
					phandle = <0x28>;
					regulator-boot-on;
					regulator-enable-ramp-delay = <0x108>;
					regulator-max-microvolt = <0x177fa0>;
					regulator-min-microvolt = <0x12ebc0>;
					regulator-name = "vm";
				};

				ldo_vmc {
					linux,phandle = <0x21>;
					phandle = <0x21>;
					regulator-boot-on;
					regulator-enable-ramp-delay = <0x2c>;
					regulator-max-microvolt = <0x325aa0>;
					regulator-min-microvolt = <0x1b7740>;
					regulator-name = "vmc";
				};

				ldo_vmch {
					linux,phandle = <0x1f>;
					phandle = <0x1f>;
					regulator-boot-on;
					regulator-enable-ramp-delay = <0x2c>;
					regulator-max-microvolt = <0x325aa0>;
					regulator-min-microvolt = <0x2c4020>;
					regulator-name = "vmch";
				};

				ldo_vrf18_0 {
					linux,phandle = <0x24>;
					phandle = <0x24>;
					regulator-enable-ramp-delay = <0xdc>;
					regulator-max-microvolt = <0x1bd8e8>;
					regulator-min-microvolt = <0x1bd8e8>;
					regulator-name = "vrf18_0";
				};

				ldo_vrf18_1 {
					linux,phandle = <0x25>;
					phandle = <0x25>;
					regulator-enable-ramp-delay = <0xdc>;
					regulator-max-microvolt = <0x1bd8e8>;
					regulator-min-microvolt = <0x124f80>;
					regulator-name = "vrf18_1";
				};

				ldo_vsim1 {
					linux,phandle = <0x1c>;
					phandle = <0x1c>;
					regulator-default-on = <0x00>;
					regulator-enable-ramp-delay = <0x108>;
					regulator-max-microvolt = <0x200b20>;
					regulator-min-microvolt = <0x19f0a0>;
					regulator-name = "vsim1";
					status = "okay";
				};

				ldo_vsim2 {
					linux,phandle = <0x1d>;
					phandle = <0x1d>;
					regulator-default-on = <0x00>;
					regulator-enable-ramp-delay = <0x108>;
					regulator-max-microvolt = <0x200b20>;
					regulator-min-microvolt = <0x19f0a0>;
					regulator-name = "vsim2";
					status = "okay";
				};

				ldo_vsram {
					linux,phandle = <0x27>;
					phandle = <0x27>;
					regulator-boot-on;
					regulator-enable-ramp-delay = <0xdc>;
					regulator-max-microvolt = <0x16caf6>;
					regulator-min-microvolt = <0xaae60>;
					regulator-name = "vsram";
					regulator-ramp-delay = <0x186a>;
				};

				ldo_vtcxo_0 {
					linux,phandle = <0x18>;
					phandle = <0x18>;
					regulator-boot-on;
					regulator-enable-ramp-delay = <0x6e>;
					regulator-max-microvolt = <0x2ab980>;
					regulator-min-microvolt = <0x2ab980>;
					regulator-name = "vtcxo_0";
				};

				ldo_vtcxo_1 {
					linux,phandle = <0x19>;
					phandle = <0x19>;
					regulator-enable-ramp-delay = <0x6e>;
					regulator-max-microvolt = <0x2ab980>;
					regulator-min-microvolt = <0x2ab980>;
					regulator-name = "vtcxo_1";
				};

				ldo_vtref {
					linux,phandle = <0x20>;
					phandle = <0x20>;
					regulator-enable-ramp-delay = <0xf0>;
					regulator-max-microvolt = <0x1b7740>;
					regulator-min-microvolt = <0x1b7740>;
					regulator-name = "vtref";
				};

				ldo_vusb33 {
					linux,phandle = <0x61>;
					phandle = <0x61>;
					regulator-boot-on;
					regulator-enable-ramp-delay = <0x108>;
					regulator-max-microvolt = <0x325aa0>;
					regulator-min-microvolt = <0x325aa0>;
					regulator-name = "vusb33";
				};
			};

			regulators_supply {
				compatible = "mediatek,mt_pmic_regulator_supply";
				vaud28-supply = <0x1a>;
				vaux18-supply = <0x17>;
				vefuse-supply = <0x1b>;
				vemc_3v3-supply = <0x1e>;
				vibr-supply = <0x23>;
				vio18-supply = <0x26>;
				vio28-supply = <0x22>;
				vm-supply = <0x28>;
				vmc-supply = <0x21>;
				vmch-supply = <0x1f>;
				vrf18_0-supply = <0x24>;
				vrf18_1-supply = <0x25>;
				vsim1-supply = <0x1c>;
				vsim2-supply = <0x1d>;
				vsram-supply = <0x27>;
				vtcxo_0-supply = <0x18>;
				vtcxo_1-supply = <0x19>;
				vtref-supply = <0x20>;
			};
		};

		perisys@0x10002000 {
			#clock-cells = <0x01>;
			compatible = "mediatek,mt6735-perisys";
			linux,phandle = <0x0a>;
			phandle = <0x0a>;
			reg = <0x10002000 0x1000>;
		};

		ptp_fsm@1100b000 {
			compatible = "mediatek,ptp_fsm_v1";
			interrupts = <0x00 0x7d 0x08>;
			reg = <0x1100b000 0x1000>;
		};

		scpsys@0x10000000 {
			#clock-cells = <0x01>;
			compatible = "mediatek,mt6735-scpsys";
			linux,phandle = <0x2d>;
			phandle = <0x2d>;
			reg = <0x10000000 0x1000 0x10006000 0x1000>;
		};

		smi_common@14017000 {
			clock-names = "smi-common\0smi-larb0\0img-larb2\0vdec0-vdec\0vdec1-larb\0venc-larb\0venc-venc\0mtcmos-ven\0mtcmos-vde\0mtcmos-isp\0mtcmos-dis";
			clocks = <0x29 0x01 0x29 0x02 0x32 0x01 0x2a 0x01 0x2a 0x02 0x2b 0x01 0x2b 0x02 0x2d 0x08 0x2d 0x07 0x2d 0x06 0x2d 0x04>;
			compatible = "mediatek,smi_common";
			reg = <0x14017000 0x1000 0x14016000 0x1000 0x16010000 0x1000 0x15001000 0x1000 0x17001000 0x1000>;
		};

		smi_larb0@14016000 {
			compatible = "mediatek,smi_larb0";
			reg = <0x14016000 0x1000>;
		};

		smi_larb1@16010000 {
			compatible = "mediatek,smi_larb1";
			interrupts = <0x00 0xb1 0x08>;
			reg = <0x16010000 0x1000>;
		};

		smi_larb2@15001000 {
			compatible = "mediatek,smi_larb2";
			interrupts = <0x00 0xb2 0x08>;
			reg = <0x15001000 0x1000>;
		};

		smi_larb3@17001000 {
			compatible = "mediatek,smi_larb3";
			interrupts = <0x00 0xca 0x08>;
			reg = <0x17001000 0x1000>;
		};

		spi@1100a000 {
			cell-index = <0x00>;
			compatible = "mediatek,mt6753-spi";
			interrupts = <0x00 0x76 0x08>;
			reg = <0x1100a000 0x1000>;
			spi-padmacro = <0x00>;
		};

		sys_cirq@10204000 {
			compatible = "mediatek,mt6735-sys_cirq";
			interrupts = <0x00 0xe7 0x08>;
			mediatek,cirq_num = <0x9f>;
			mediatek,spi_start_offset = <0x48>;
			reg = <0x10204000 0x1000>;
		};

		timer {
			clock-frequency = <0xc65d40>;
			compatible = "arm,armv8-timer";
			interrupts = <0x01 0x0d 0x08 0x01 0x0e 0x08 0x01 0x0b 0x08 0x01 0x0a 0x08>;
		};

		topckgen@0x10210000 {
			#clock-cells = <0x01>;
			compatible = "mediatek,mt6735-topckgen";
			linux,phandle = <0x2c>;
			phandle = <0x2c>;
			reg = <0x10210000 0x1000>;
		};

		toprgu@10212000 {
			compatible = "mediatek,mt6735-rgu";
			interrupts = <0x00 0x80 0x02>;
			reg = <0x10212000 0x1000>;
		};

		vdec@16020000 {
			compatible = "mediatek,mt6735-vdec";
			interrupts = <0x00 0xb3 0x08>;
			reg = <0x16020000 0x10000>;
		};

		vdec_gcon@16000000 {
			clock-names = "MT_CG_DISP0_SMI_COMMON\0MT_CG_VDEC0_VDEC\0MT_CG_VDEC1_LARB\0MT_CG_VENC_VENC\0MT_CG_VENC_LARB\0MT_CG_TOP_MUX_VDEC\0MT_CG_TOP_SYSPLL1_D2\0MT_CG_TOP_SYSPLL1_D4\0MT_SCP_SYS_VDE\0MT_SCP_SYS_VEN\0MT_SCP_SYS_DIS";
			clocks = <0x29 0x01 0x2a 0x01 0x2a 0x02 0x2b 0x02 0x2b 0x01 0x2c 0x06 0x2c 0x32 0x2c 0x33 0x2d 0x07 0x2d 0x08 0x2d 0x04>;
			compatible = "mediatek,mt6735-vdec_gcon";
			interrupts = <0x00 0xb3 0x08>;
			reg = <0x16000000 0x1000>;
		};

		vdecsys@0x16000000 {
			#clock-cells = <0x01>;
			compatible = "mediatek,mt6735-vdecsys";
			interrupts = <0x00 0xb3 0x08>;
			linux,phandle = <0x2a>;
			phandle = <0x2a>;
			reg = <0x16000000 0x1000>;
		};

		venc@17002000 {
			compatible = "mediatek,mt6735-venc";
			interrupts = <0x00 0xb4 0x08>;
			reg = <0x17002000 0x1000>;
		};

		venc_gcon@17000000 {
			compatible = "mediatek,mt6735-venc_gcon";
			interrupts = <0x00 0xb4 0x08>;
			reg = <0x17000000 0x1000>;
		};

		vencsys@0x17000000 {
			#clock-cells = <0x01>;
			compatible = "mediatek,mt6735-vencsys";
			interrupts = <0x00 0xb4 0x08>;
			linux,phandle = <0x2b>;
			phandle = <0x2b>;
			reg = <0x17000000 0x1000>;
		};
	};

	trusty {
		#address-cells = <0x02>;
		#size-cells = <0x02>;
		compatible = "android,trusty-smc-v1";
		ranges;

		irq {
			compatible = "android,trusty-irq-v1";
			ppi-interrupt-parent = <0x01>;
		};

		log {
			compatible = "android,trusty-log-v1";
		};

		mtee {
			compatible = "mediatek,trusty-mtee-v1";
		};

		virtio {
			compatible = "android,trusty-virtio-v1";
		};
	};

	utos {
		compatible = "microtrust,utos";
		interrupts = <0x00 0xf4 0x01 0x00 0xf5 0x01 0x00 0xf6 0x01 0x00 0xfa 0x01 0x00 0xfb 0x01 0x00 0xfc 0x01 0x00 0xfd 0x01 0x00 0xff 0x01>;
	};

	vcorefs {
		clock-names = "mux_axi\0syspll_d5\0syspll1_d4";
		clocks = <0x2c 0x01 0x2c 0x30 0x2c 0x33>;
		compatible = "mediatek,mt6735-vcorefs";
	};

	vibrator@0 {
		compatible = "mediatek,vibrator";
		vib_limit = <0x09>;
		vib_timer = <0x19>;
		vib_vol = <0x06>;
	};
};
